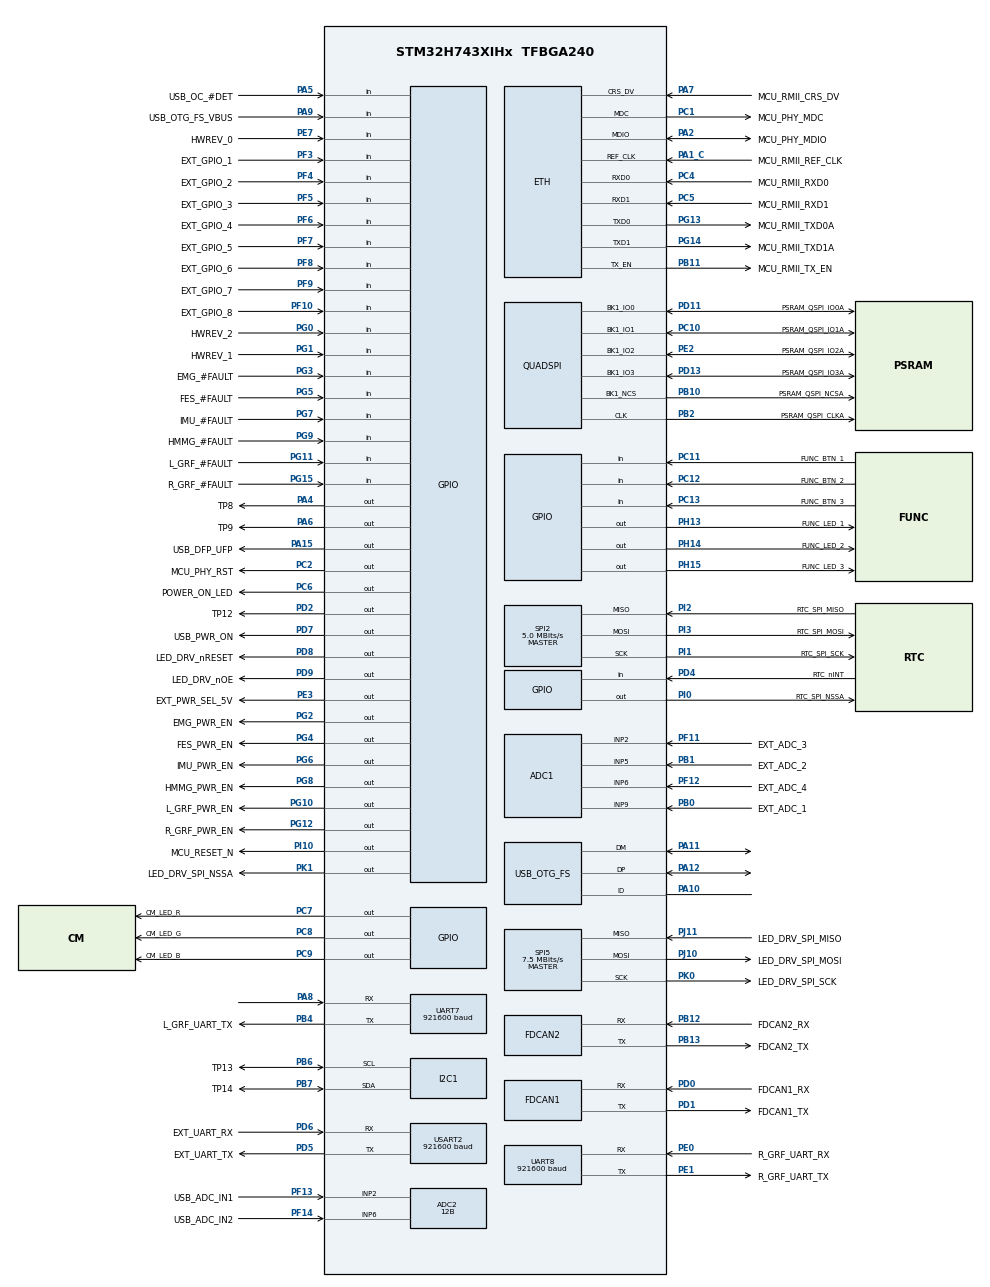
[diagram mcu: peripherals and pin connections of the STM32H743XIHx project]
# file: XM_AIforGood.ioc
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ADC1.Channel-6\#ChannelRegularConversion=ADC_CHANNEL_2
ADC1.Channel-7\#ChannelRegularConversion=ADC_CHANNEL_5
ADC1.Channel-8\#ChannelRegularConversion=ADC_CHANNEL_6
ADC1.Channel-9\#ChannelRegularConversion=ADC_CHANNEL_9
ADC1.ClockPrescaler=ADC_CLOCK_ASYNC_DIV4
ADC1.ConversionDataManagement=ADC_CONVERSIONDATA_DMA_CIRCULAR
ADC1.EOCSelection=ADC_EOC_SEQ_CONV
ADC1.ExternalTrigConv=ADC_EXTERNALTRIG_T2_TRGO
ADC1.NbrOfConversion=4
ADC1.NbrOfConversionFlag=1
ADC1.OffsetNumber-6\#ChannelRegularConversion=ADC_OFFSET_NONE
ADC1.OffsetNumber-7\#ChannelRegularConversion=ADC_OFFSET_NONE
ADC1.OffsetNumber-8\#ChannelRegularConversion=ADC_OFFSET_NONE
ADC1.OffsetNumber-9\#ChannelRegularConversion=ADC_OFFSET_NONE
ADC1.OffsetSignedSaturation-6\#ChannelRegularConversion=DISABLE
ADC1.OffsetSignedSaturation-7\#ChannelRegularConversion=DISABLE
ADC1.OffsetSignedSaturation-8\#ChannelRegularConversion=DISABLE
ADC1.OffsetSignedSaturation-9\#ChannelRegularConversion=DISABLE
ADC1.Overrun=ADC_OVR_DATA_OVERWRITTEN
ADC1.Rank-6\#ChannelRegularConversion=1
ADC1.Rank-7\#ChannelRegularConversion=2
ADC1.Rank-8\#ChannelRegularConversion=3
ADC1.Rank-9\#ChannelRegularConversion=4
ADC1.SamplingTime-6\#ChannelRegularConversion=ADC_SAMPLETIME_387CYCLES_5
ADC1.SamplingTime-7\#ChannelRegularConversion=ADC_SAMPLETIME_387CYCLES_5
ADC1.SamplingTime-8\#ChannelRegularConversion=ADC_SAMPLETIME_387CYCLES_5
ADC1.SamplingTime-9\#ChannelRegularConversion=ADC_SAMPLETIME_387CYCLES_5
ADC1.master=1
ADC2.Channel-2\#ChannelRegularConversion=ADC_CHANNEL_2
ADC2.Channel-3\#ChannelRegularConversion=ADC_CHANNEL_6
ADC2.ClockPrescaler=ADC_CLOCK_ASYNC_DIV4
ADC2.ConversionDataManagement=ADC_CONVERSIONDATA_DMA_CIRCULAR
ADC2.EOCSelection=ADC_EOC_SEQ_CONV
ADC2.ExternalTrigConv=ADC_EXTERNALTRIG_T2_TRGO
ADC2.NbrOfConversion=2
ADC2.NbrOfConversionFlag=1
ADC2.OffsetNumber-2\#ChannelRegularConversion=ADC_OFFSET_NONE
ADC2.OffsetNumber-3\#ChannelRegularConversion=ADC_OFFSET_NONE
ADC2.OffsetSignedSaturation-2\#ChannelRegularConversion=DISABLE
ADC2.Overrun=ADC_OVR_DATA_OVERWRITTEN
ADC2.Rank-2\#ChannelRegularConversion=1
ADC2.Rank-3\#ChannelRegularConversion=2
ADC2.Resolution=ADC_RESOLUTION_12B
ADC2.SamplingTime-2\#ChannelRegularConversion=ADC_SAMPLETIME_810CYCLES_5
ADC2.SamplingTime-3\#ChannelRegularConversion=ADC_SAMPLETIME_810CYCLES_5
CORTEX_M7.AccessPermission-Cortex_Memory_Protection_Unit_Region0_Settings=MPU_REGION_FULL_ACCESS
CORTEX_M7.AccessPermission-Cortex_Memory_Protection_Unit_Region1_Settings=MPU_REGION_FULL_ACCESS
CORTEX_M7.AccessPermission-Cortex_Memory_Protection_Unit_Region2_Settings=MPU_REGION_FULL_ACCESS
CORTEX_M7.AccessPermission-Cortex_Memory_Protection_Unit_Region3_Settings=MPU_REGION_FULL_ACCESS
CORTEX_M7.BaseAddress-Cortex_Memory_Protection_Unit_Region0_Settings=0x30000000
CORTEX_M7.BaseAddress-Cortex_Memory_Protection_Unit_Region1_Settings=0x30040000
CORTEX_M7.BaseAddress-Cortex_Memory_Protection_Unit_Region2_Settings=0x38000000
CORTEX_M7.BaseAddress-Cortex_Memory_Protection_Unit_Region3_Settings=0x90000000
CORTEX_M7.CPU_DCache=Enabled
CORTEX_M7.CPU_ICache=Enabled
CORTEX_M7.DisableExec-Cortex_Memory_Protection_Unit_Region0_Settings=MPU_INSTRUCTION_ACCESS_DISABLE
CORTEX_M7.DisableExec-Cortex_Memory_Protection_Unit_Region1_Settings=MPU_INSTRUCTION_ACCESS_DISABLE
CORTEX_M7.DisableExec-Cortex_Memory_Protection_Unit_Region2_Settings=MPU_INSTRUCTION_ACCESS_DISABLE
CORTEX_M7.Enable-Cortex_Memory_Protection_Unit_Region0_Settings=MPU_REGION_ENABLE
CORTEX_M7.Enable-Cortex_Memory_Protection_Unit_Region1_Settings=MPU_REGION_ENABLE
CORTEX_M7.Enable-Cortex_Memory_Protection_Unit_Region2_Settings=MPU_REGION_ENABLE
CORTEX_M7.Enable-Cortex_Memory_Protection_Unit_Region3_Settings=MPU_REGION_ENABLE
CORTEX_M7.IsBufferable-Cortex_Memory_Protection_Unit_Region0_Settings=MPU_ACCESS_NOT_BUFFERABLE
CORTEX_M7.IsCacheable-Cortex_Memory_Protection_Unit_Region0_Settings=MPU_ACCESS_NOT_CACHEABLE
CORTEX_M7.IsCacheable-Cortex_Memory_Protection_Unit_Region3_Settings=MPU_ACCESS_CACHEABLE
CORTEX_M7.IsShareable-Cortex_Memory_Protection_Unit_Region0_Settings=MPU_ACCESS_SHAREABLE
CORTEX_M7.IsShareable-Cortex_Memory_Protection_Unit_Region1_Settings=MPU_ACCESS_SHAREABLE
CORTEX_M7.IsShareable-Cortex_Memory_Protection_Unit_Region2_Settings=MPU_ACCESS_SHAREABLE
CORTEX_M7.MPU_Control=MPU_HFNMI_PRIVDEF
CORTEX_M7.Size-Cortex_Memory_Protection_Unit_Region0_Settings=MPU_REGION_SIZE_256KB
CORTEX_M7.Size-Cortex_Memory_Protection_Unit_Region1_Settings=MPU_REGION_SIZE_32KB
CORTEX_M7.Size-Cortex_Memory_Protection_Unit_Region2_Settings=MPU_REGION_SIZE_64KB
CORTEX_M7.Size-Cortex_Memory_Protection_Unit_Region3_Settings=MPU_REGION_SIZE_8MB
CORTEX_M7.TypeExtField-Cortex_Memory_Protection_Unit_Region0_Settings=MPU_TEX_LEVEL1
CORTEX_M7.TypeExtField-Cortex_Memory_Protection_Unit_Region1_Settings=MPU_TEX_LEVEL1
CORTEX_M7.TypeExtField-Cortex_Memory_Protection_Unit_Region2_Settings=MPU_TEX_LEVEL1
Dma.ADC1.1.Direction=DMA_PERIPH_TO_MEMORY
Dma.ADC1.1.EventEnable=DISABLE
Dma.ADC1.1.FIFOMode=DMA_FIFOMODE_DISABLE
Dma.ADC1.1.Instance=DMA1_Stream0
Dma.ADC1.1.MemDataAlignment=DMA_MDATAALIGN_HALFWORD
Dma.ADC1.1.MemInc=DMA_MINC_ENABLE
Dma.ADC1.1.Mode=DMA_CIRCULAR
Dma.ADC1.1.PeriphDataAlignment=DMA_PDATAALIGN_HALFWORD
Dma.ADC1.1.PeriphInc=DMA_PINC_DISABLE
Dma.ADC1.1.Polarity=HAL_DMAMUX_REQ_GEN_RISING
Dma.ADC1.1.Priority=DMA_PRIORITY_LOW
Dma.ADC1.1.RequestNumber=1
Dma.ADC1.1.SignalID=NONE
Dma.ADC1.1.SyncEnable=DISABLE
Dma.ADC1.1.SyncPolarity=HAL_DMAMUX_SYNC_NO_EVENT
Dma.ADC1.1.SyncRequestNumber=1
Dma.ADC1.1.SyncSignalID=NONE
Dma.ADC2.2.Direction=DMA_PERIPH_TO_MEMORY
Dma.ADC2.2.EventEnable=DISABLE
Dma.ADC2.2.FIFOMode=DMA_FIFOMODE_DISABLE
Dma.ADC2.2.Instance=DMA1_Stream1
Dma.ADC2.2.MemDataAlignment=DMA_MDATAALIGN_HALFWORD
Dma.ADC2.2.MemInc=DMA_MINC_ENABLE
Dma.ADC2.2.Mode=DMA_CIRCULAR
Dma.ADC2.2.PeriphDataAlignment=DMA_PDATAALIGN_HALFWORD
Dma.ADC2.2.PeriphInc=DMA_PINC_DISABLE
Dma.ADC2.2.Polarity=HAL_DMAMUX_REQ_GEN_RISING
Dma.ADC2.2.Priority=DMA_PRIORITY_LOW
Dma.ADC2.2.RequestNumber=1
Dma.ADC2.2.SignalID=NONE
Dma.ADC2.2.SyncEnable=DISABLE
Dma.ADC2.2.SyncPolarity=HAL_DMAMUX_SYNC_NO_EVENT
Dma.ADC2.2.SyncRequestNumber=1
Dma.ADC2.2.SyncSignalID=NONE
Dma.Request0=UART8_RX
Dma.Request1=ADC1
Dma.Request10=UART7_TX
Dma.Request11=UART8_TX
Dma.Request2=ADC2
Dma.Request3=UART7_RX
Dma.Request4=USART2_RX
Dma.Request5=SPI2_TX
Dma.Request6=SPI2_RX
Dma.Request7=SPI5_TX
Dma.Request8=SPI5_RX
Dma.Request9=USART2_TX
Dma.SPI2_RX.6.Direction=DMA_PERIPH_TO_MEMORY
Dma.SPI2_RX.6.EventEnable=DISABLE
Dma.SPI2_RX.6.FIFOMode=DMA_FIFOMODE_DISABLE
Dma.SPI2_RX.6.Instance=DMA1_Stream6
Dma.SPI2_RX.6.MemDataAlignment=DMA_MDATAALIGN_BYTE
Dma.SPI2_RX.6.MemInc=DMA_MINC_ENABLE
Dma.SPI2_RX.6.Mode=DMA_NORMAL
Dma.SPI2_RX.6.PeriphDataAlignment=DMA_PDATAALIGN_BYTE
Dma.SPI2_RX.6.PeriphInc=DMA_PINC_DISABLE
Dma.SPI2_RX.6.Polarity=HAL_DMAMUX_REQ_GEN_RISING
Dma.SPI2_RX.6.Priority=DMA_PRIORITY_LOW
Dma.SPI2_RX.6.RequestNumber=1
Dma.SPI2_RX.6.SignalID=NONE
Dma.SPI2_RX.6.SyncEnable=DISABLE
Dma.SPI2_RX.6.SyncPolarity=HAL_DMAMUX_SYNC_NO_EVENT
Dma.SPI2_RX.6.SyncRequestNumber=1
Dma.SPI2_RX.6.SyncSignalID=NONE
Dma.SPI2_TX.5.Direction=DMA_MEMORY_TO_PERIPH
Dma.SPI2_TX.5.EventEnable=DISABLE
Dma.SPI2_TX.5.FIFOMode=DMA_FIFOMODE_DISABLE
Dma.SPI2_TX.5.Instance=DMA1_Stream5
Dma.SPI2_TX.5.MemDataAlignment=DMA_MDATAALIGN_BYTE
Dma.SPI2_TX.5.MemInc=DMA_MINC_ENABLE
Dma.SPI2_TX.5.Mode=DMA_NORMAL
Dma.SPI2_TX.5.PeriphDataAlignment=DMA_PDATAALIGN_BYTE
Dma.SPI2_TX.5.PeriphInc=DMA_PINC_DISABLE
Dma.SPI2_TX.5.Polarity=HAL_DMAMUX_REQ_GEN_RISING
Dma.SPI2_TX.5.Priority=DMA_PRIORITY_LOW
Dma.SPI2_TX.5.RequestNumber=1
Dma.SPI2_TX.5.SignalID=NONE
Dma.SPI2_TX.5.SyncEnable=DISABLE
Dma.SPI2_TX.5.SyncPolarity=HAL_DMAMUX_SYNC_NO_EVENT
Dma.SPI2_TX.5.SyncRequestNumber=1
Dma.SPI2_TX.5.SyncSignalID=NONE
Dma.SPI5_RX.8.Direction=DMA_PERIPH_TO_MEMORY
Dma.SPI5_RX.8.EventEnable=DISABLE
Dma.SPI5_RX.8.FIFOMode=DMA_FIFOMODE_DISABLE
Dma.SPI5_RX.8.Instance=DMA2_Stream0
Dma.SPI5_RX.8.MemDataAlignment=DMA_MDATAALIGN_BYTE
Dma.SPI5_RX.8.MemInc=DMA_MINC_ENABLE
Dma.SPI5_RX.8.Mode=DMA_NORMAL
Dma.SPI5_RX.8.PeriphDataAlignment=DMA_PDATAALIGN_BYTE
Dma.SPI5_RX.8.PeriphInc=DMA_PINC_DISABLE
Dma.SPI5_RX.8.Polarity=HAL_DMAMUX_REQ_GEN_RISING
Dma.SPI5_RX.8.Priority=DMA_PRIORITY_LOW
Dma.SPI5_RX.8.RequestNumber=1
Dma.SPI5_RX.8.SignalID=NONE
Dma.SPI5_RX.8.SyncEnable=DISABLE
Dma.SPI5_RX.8.SyncPolarity=HAL_DMAMUX_SYNC_NO_EVENT
Dma.SPI5_RX.8.SyncRequestNumber=1
Dma.SPI5_RX.8.SyncSignalID=NONE
Dma.SPI5_TX.7.Direction=DMA_MEMORY_TO_PERIPH
Dma.SPI5_TX.7.EventEnable=DISABLE
Dma.SPI5_TX.7.FIFOMode=DMA_FIFOMODE_DISABLE
Dma.SPI5_TX.7.Instance=DMA1_Stream7
Dma.SPI5_TX.7.MemDataAlignment=DMA_MDATAALIGN_BYTE
Dma.SPI5_TX.7.MemInc=DMA_MINC_ENABLE
Dma.SPI5_TX.7.Mode=DMA_NORMAL
Dma.SPI5_TX.7.PeriphDataAlignment=DMA_PDATAALIGN_BYTE
Dma.SPI5_TX.7.PeriphInc=DMA_PINC_DISABLE
Dma.SPI5_TX.7.Polarity=HAL_DMAMUX_REQ_GEN_RISING
Dma.SPI5_TX.7.Priority=DMA_PRIORITY_LOW
Dma.SPI5_TX.7.RequestNumber=1
Dma.SPI5_TX.7.SignalID=NONE
Dma.SPI5_TX.7.SyncEnable=DISABLE
Dma.SPI5_TX.7.SyncPolarity=HAL_DMAMUX_SYNC_NO_EVENT
Dma.SPI5_TX.7.SyncRequestNumber=1
Dma.SPI5_TX.7.SyncSignalID=NONE
Dma.UART7_RX.3.Direction=DMA_PERIPH_TO_MEMORY
Dma.UART7_RX.3.EventEnable=DISABLE
Dma.UART7_RX.3.FIFOMode=DMA_FIFOMODE_ENABLE
Dma.UART7_RX.3.FIFOThreshold=DMA_FIFO_THRESHOLD_1QUARTERFULL
Dma.UART7_RX.3.Instance=DMA1_Stream2
Dma.UART7_RX.3.MemBurst=DMA_MBURST_SINGLE
Dma.UART7_RX.3.MemDataAlignment=DMA_MDATAALIGN_BYTE
Dma.UART7_RX.3.MemInc=DMA_MINC_ENABLE
Dma.UART7_RX.3.Mode=DMA_CIRCULAR
Dma.UART7_RX.3.PeriphBurst=DMA_PBURST_SINGLE
Dma.UART7_RX.3.PeriphDataAlignment=DMA_PDATAALIGN_BYTE
Dma.UART7_RX.3.PeriphInc=DMA_PINC_DISABLE
Dma.UART7_RX.3.Polarity=HAL_DMAMUX_REQ_GEN_RISING
Dma.UART7_RX.3.Priority=DMA_PRIORITY_VERY_HIGH
Dma.UART7_RX.3.RequestNumber=1
Dma.UART7_RX.3.SignalID=NONE
Dma.UART7_RX.3.SyncEnable=DISABLE
Dma.UART7_RX.3.SyncPolarity=HAL_DMAMUX_SYNC_NO_EVENT
Dma.UART7_RX.3.SyncRequestNumber=1
Dma.UART7_RX.3.SyncSignalID=NONE
Dma.UART7_TX.10.Direction=DMA_MEMORY_TO_PERIPH
Dma.UART7_TX.10.EventEnable=DISABLE
Dma.UART7_TX.10.FIFOMode=DMA_FIFOMODE_DISABLE
Dma.UART7_TX.10.Instance=DMA2_Stream2
Dma.UART7_TX.10.MemDataAlignment=DMA_MDATAALIGN_BYTE
Dma.UART7_TX.10.MemInc=DMA_MINC_ENABLE
Dma.UART7_TX.10.Mode=DMA_NORMAL
Dma.UART7_TX.10.PeriphDataAlignment=DMA_PDATAALIGN_BYTE
Dma.UART7_TX.10.PeriphInc=DMA_PINC_DISABLE
Dma.UART7_TX.10.Polarity=HAL_DMAMUX_REQ_GEN_RISING
Dma.UART7_TX.10.Priority=DMA_PRIORITY_LOW
Dma.UART7_TX.10.RequestNumber=1
Dma.UART7_TX.10.SignalID=NONE
Dma.UART7_TX.10.SyncEnable=DISABLE
Dma.UART7_TX.10.SyncPolarity=HAL_DMAMUX_SYNC_NO_EVENT
Dma.UART7_TX.10.SyncRequestNumber=1
Dma.UART7_TX.10.SyncSignalID=NONE
Dma.UART8_RX.0.Direction=DMA_PERIPH_TO_MEMORY
Dma.UART8_RX.0.EventEnable=DISABLE
Dma.UART8_RX.0.FIFOMode=DMA_FIFOMODE_ENABLE
Dma.UART8_RX.0.FIFOThreshold=DMA_FIFO_THRESHOLD_1QUARTERFULL
Dma.UART8_RX.0.Instance=DMA1_Stream3
Dma.UART8_RX.0.MemBurst=DMA_MBURST_SINGLE
Dma.UART8_RX.0.MemDataAlignment=DMA_MDATAALIGN_BYTE
Dma.UART8_RX.0.MemInc=DMA_MINC_ENABLE
Dma.UART8_RX.0.Mode=DMA_CIRCULAR
Dma.UART8_RX.0.PeriphBurst=DMA_PBURST_SINGLE
Dma.UART8_RX.0.PeriphDataAlignment=DMA_PDATAALIGN_BYTE
Dma.UART8_RX.0.PeriphInc=DMA_PINC_DISABLE
Dma.UART8_RX.0.Polarity=HAL_DMAMUX_REQ_GEN_RISING
Dma.UART8_RX.0.Priority=DMA_PRIORITY_VERY_HIGH
Dma.UART8_RX.0.RequestNumber=1
Dma.UART8_RX.0.SignalID=NONE
Dma.UART8_RX.0.SyncEnable=DISABLE
Dma.UART8_RX.0.SyncPolarity=HAL_DMAMUX_SYNC_NO_EVENT
Dma.UART8_RX.0.SyncRequestNumber=1
Dma.UART8_RX.0.SyncSignalID=NONE
Dma.UART8_TX.11.Direction=DMA_MEMORY_TO_PERIPH
Dma.UART8_TX.11.EventEnable=DISABLE
Dma.UART8_TX.11.FIFOMode=DMA_FIFOMODE_DISABLE
Dma.UART8_TX.11.Instance=DMA2_Stream3
Dma.UART8_TX.11.MemDataAlignment=DMA_MDATAALIGN_BYTE
Dma.UART8_TX.11.MemInc=DMA_MINC_ENABLE
Dma.UART8_TX.11.Mode=DMA_NORMAL
Dma.UART8_TX.11.PeriphDataAlignment=DMA_PDATAALIGN_BYTE
Dma.UART8_TX.11.PeriphInc=DMA_PINC_DISABLE
Dma.UART8_TX.11.Polarity=HAL_DMAMUX_REQ_GEN_RISING
Dma.UART8_TX.11.Priority=DMA_PRIORITY_LOW
Dma.UART8_TX.11.RequestNumber=1
Dma.UART8_TX.11.SignalID=NONE
Dma.UART8_TX.11.SyncEnable=DISABLE
Dma.UART8_TX.11.SyncPolarity=HAL_DMAMUX_SYNC_NO_EVENT
Dma.UART8_TX.11.SyncRequestNumber=1
Dma.UART8_TX.11.SyncSignalID=NONE
Dma.USART2_RX.4.Direction=DMA_PERIPH_TO_MEMORY
Dma.USART2_RX.4.EventEnable=DISABLE
Dma.USART2_RX.4.FIFOMode=DMA_FIFOMODE_ENABLE
Dma.USART2_RX.4.FIFOThreshold=DMA_FIFO_THRESHOLD_1QUARTERFULL
Dma.USART2_RX.4.Instance=DMA1_Stream4
Dma.USART2_RX.4.MemBurst=DMA_MBURST_SINGLE
Dma.USART2_RX.4.MemDataAlignment=DMA_MDATAALIGN_BYTE
Dma.USART2_RX.4.MemInc=DMA_MINC_ENABLE
Dma.USART2_RX.4.Mode=DMA_CIRCULAR
Dma.USART2_RX.4.PeriphBurst=DMA_PBURST_SINGLE
Dma.USART2_RX.4.PeriphDataAlignment=DMA_PDATAALIGN_BYTE
Dma.USART2_RX.4.PeriphInc=DMA_PINC_DISABLE
Dma.USART2_RX.4.Polarity=HAL_DMAMUX_REQ_GEN_RISING
Dma.USART2_RX.4.Priority=DMA_PRIORITY_VERY_HIGH
Dma.USART2_RX.4.RequestNumber=1
Dma.USART2_RX.4.SignalID=NONE
Dma.USART2_RX.4.SyncEnable=DISABLE
Dma.USART2_RX.4.SyncPolarity=HAL_DMAMUX_SYNC_NO_EVENT
Dma.USART2_RX.4.SyncRequestNumber=1
Dma.USART2_RX.4.SyncSignalID=NONE
Dma.USART2_TX.9.Direction=DMA_MEMORY_TO_PERIPH
Dma.USART2_TX.9.EventEnable=DISABLE
Dma.USART2_TX.9.FIFOMode=DMA_FIFOMODE_DISABLE
Dma.USART2_TX.9.Instance=DMA2_Stream1
Dma.USART2_TX.9.MemDataAlignment=DMA_MDATAALIGN_BYTE
Dma.USART2_TX.9.MemInc=DMA_MINC_ENABLE
Dma.USART2_TX.9.Mode=DMA_NORMAL
Dma.USART2_TX.9.PeriphDataAlignment=DMA_PDATAALIGN_BYTE
Dma.USART2_TX.9.PeriphInc=DMA_PINC_DISABLE
Dma.USART2_TX.9.Polarity=HAL_DMAMUX_REQ_GEN_RISING
Dma.USART2_TX.9.Priority=DMA_PRIORITY_LOW
Dma.USART2_TX.9.RequestNumber=1
Dma.USART2_TX.9.SignalID=NONE
Dma.USART2_TX.9.SyncEnable=DISABLE
Dma.USART2_TX.9.SyncPolarity=HAL_DMAMUX_SYNC_NO_EVENT
Dma.USART2_TX.9.SyncRequestNumber=1
Dma.USART2_TX.9.SyncSignalID=NONE
ETH.ETH_RX_DESC_CNT=8
ETH.ETH_TX_DESC_CNT=8
ETH.MediaInterface=HAL_ETH_RMII_MODE
FATFS._FS_RPATH=0
FATFS._MAX_SS=4096
FATFS._USE_LFN=2
FDCAN1.AutoRetransmission=ENABLE
FDCAN1.CalculateBaudRateNominal=1000000
FDCAN1.CalculateTimeBitNominal=1000
FDCAN1.CalculateTimeQuantumNominal=125.0
FDCAN1.DataSyncJumpWidth=4
FDCAN1.DataTimeSeg1=11
FDCAN1.DataTimeSeg2=4
FDCAN1.FrameFormat=FDCAN_FRAME_FD_BRS
FDCAN1.NominalPrescaler=10
FDCAN1.NominalSyncJumpWidth=2
FDCAN1.NominalTimeSeg1=5
FDCAN1.NominalTimeSeg2=2
FDCAN1.RxBufferSize=FDCAN_DATA_BYTES_64
FDCAN1.RxBuffersNbr=0
FDCAN1.RxFifo0ElmtSize=FDCAN_DATA_BYTES_64
FDCAN1.RxFifo0ElmtsNbr=37
FDCAN1.RxFifo1ElmtSize=FDCAN_DATA_BYTES_64
FDCAN1.RxFifo1ElmtsNbr=0
FDCAN1.StdFiltersNbr=28
FDCAN1.TransmitPause=ENABLE
FDCAN1.TxBuffersNbr=0
FDCAN1.TxElmtSize=FDCAN_DATA_BYTES_64
FDCAN1.TxEventsNbr=0
FDCAN1.TxFifoQueueElmtsNbr=32
FDCAN1.TxFifoQueueMode=FDCAN_TX_QUEUE_OPERATION
FDCAN2.AutoRetransmission=ENABLE
FDCAN2.CalculateBaudRateNominal=1000000
FDCAN2.CalculateTimeBitNominal=1000
FDCAN2.CalculateTimeQuantumNominal=125.0
FDCAN2.DataSyncJumpWidth=4
FDCAN2.DataTimeSeg1=11
FDCAN2.DataTimeSeg2=4
FDCAN2.FrameFormat=FDCAN_FRAME_FD_BRS
FDCAN2.MessageRAMOffset=1280
FDCAN2.NominalPrescaler=10
FDCAN2.NominalSyncJumpWidth=2
FDCAN2.NominalTimeSeg1=5
FDCAN2.NominalTimeSeg2=2
FDCAN2.RxBufferSize=FDCAN_DATA_BYTES_64
FDCAN2.RxFifo0ElmtSize=FDCAN_DATA_BYTES_64
FDCAN2.RxFifo0ElmtsNbr=37
FDCAN2.RxFifo1ElmtSize=FDCAN_DATA_BYTES_64
FDCAN2.StdFiltersNbr=28
FDCAN2.TransmitPause=ENABLE
FDCAN2.TxElmtSize=FDCAN_DATA_BYTES_64
FDCAN2.TxFifoQueueElmtsNbr=32
FDCAN2.TxFifoQueueMode=FDCAN_TX_QUEUE_OPERATION
FREERTOS.HEAP_NUMBER=4
FREERTOS.Tasks01=DefaultTask,8,2048,StartDefaultTask,Default,NULL,Static,DefaultTaskBuffer,DefaultTaskControlBlock;UserTask,54,8192,StartUserTask,As weak,NULL,Dynamic,NULL,NULL;StartupTask,55,512,StartStartupTask,As weak,NULL,Dynamic,NULL,NULL
FREERTOS.configCHECK_FOR_STACK_OVERFLOW=2
FREERTOS.configENABLE_FPU=1
FREERTOS.configTOTAL_HEAP_SIZE=102400
FREERTOS.configUSE_NEWLIB_REENTRANT=1
I2C1.Timing=0x307075B1
LWIP.DEFAULT_RAW_RECVMBOX_SIZE=6
LWIP.DEFAULT_TCP_RECVMBOX_SIZE=6
LWIP.DEFAULT_THREAD_PRIO=24
LWIP.DEFAULT_THREAD_STACKSIZE=512
LWIP.DEFAULT_UDP_RECVMBOX_SIZE=24
LWIP.DHCP_DEBUG=LWIP_DBG_OFF
LWIP.ETHARP_DEBUG=LWIP_DBG_OFF
LWIP.GATEWAY_ADDRESS=192.168.010.001
LWIP.IP_ADDRESS=192.168.010.010
LWIP.IP_DEBUG=LWIP_DBG_OFF
LWIP.IP_FRAG=0
LWIP.IP_REASSEMBLY=0
LWIP.LWIP_COMPAT_SOCKETS=0
LWIP.LWIP_DBG_MIN_LEVEL=LWIP_DBG_LEVEL_ALL
LWIP.LWIP_DBG_TYPES_ON=LWIP_DBG_OFF
LWIP.LWIP_DHCP=0
LWIP.LWIP_NETIF_API=1
LWIP.LWIP_NETIF_HOSTNAME=1
LWIP.LWIP_NETIF_HOSTNAME_NAME=XM10-Rev2.0
LWIP.LWIP_NETIF_STATUS_CALLBACK=1
LWIP.LWIP_NETIF_TX_SINGLE_PBUF=1
LWIP.LWIP_POSIX_SOCKETS_IO_NAMES=0
LWIP.LWIP_RAM_HEAP_POINTER=0x30030000
LWIP.LWIP_SINGLE_NETIF=1
LWIP.LWIP_SOCKET=0
LWIP.LWIP_SO_RCVTIMEO=0
LWIP.LWIP_SO_SNDTIMEO=0
LWIP.LWIP_TCP=0
LWIP.LWIP_TCPIP_CORE_LOCKING=1
LWIP.MEMP_NUM_NETBUF=16
LWIP.MEMP_NUM_NETCONN=8
LWIP.MEMP_NUM_PBUF=32
LWIP.MEMP_NUM_REASSDATA=1
LWIP.MEMP_NUM_SYS_TIMEOUT=6
LWIP.MEMP_NUM_TCPIP_MSG_API=12
LWIP.MEMP_NUM_TCPIP_MSG_INPKT=16
LWIP.MEMP_NUM_TCP_PCB_LISTEN=10
LWIP.MEMP_NUM_TCP_SEG=24
LWIP.MEMP_NUM_UDP_PCB=6
LWIP.MEM_DEBUG=LWIP_DBG_OFF
LWIP.MEM_SIZE=32768
LWIP.NETIF_DEBUG=LWIP_DBG_OFF
LWIP.NETMASK_ADDRESS=255.255.255.000
LWIP.PBUF_DEBUG=LWIP_DBG_OFF
LWIP.PBUF_POOL_BUFSIZE=1524
LWIP.PBUF_POOL_SIZE=32
LWIP.TCPIP_DEBUG=LWIP_DBG_OFF
LWIP.TCPIP_MBOX_SIZE=16
LWIP.TCPIP_THREAD_NAME="TCP/IP"
LWIP.TCPIP_THREAD_PRIO=32
LWIP.TCP_MSS=1460
LWIP.TCP_QUEUE_OOSEQ=1
LWIP.TCP_SND_BUF=8760
LWIP.TCP_WND=14600
LWIP.UDP_DEBUG=LWIP_DBG_OFF
LWIP.Version=v2.2.1_Cube
Mcu.Family=STM32H7
Mcu.Name=STM32H743XIHx
Mcu.Package=TFBGA240
Mdma.MDMA_Channel0.QUADSPI_FIFO_TH.0.BlockCount=0
Mdma.MDMA_Channel0.QUADSPI_FIFO_TH.0.BlockDataLength=0
Mdma.MDMA_Channel0.QUADSPI_FIFO_TH.0.BufferTransferLength=4
Mdma.MDMA_Channel0.QUADSPI_FIFO_TH.0.CircularMode=MDMA_LINEAR_LIST
Mdma.MDMA_Channel0.QUADSPI_FIFO_TH.0.DataAlignment=MDMA_DATAALIGN_PACKENABLE
Mdma.MDMA_Channel0.QUADSPI_FIFO_TH.0.DestBlockAddressOffset=0
Mdma.MDMA_Channel0.QUADSPI_FIFO_TH.0.DestBurst=MDMA_DEST_BURST_SINGLE
Mdma.MDMA_Channel0.QUADSPI_FIFO_TH.0.DestDataSize=MDMA_DEST_DATASIZE_BYTE
Mdma.MDMA_Channel0.QUADSPI_FIFO_TH.0.DestinationInc=MDMA_DEST_INC_BYTE
Mdma.MDMA_Channel0.QUADSPI_FIFO_TH.0.DstAddress=0
Mdma.MDMA_Channel0.QUADSPI_FIFO_TH.0.Endianness=MDMA_LITTLE_ENDIANNESS_PRESERVE
Mdma.MDMA_Channel0.QUADSPI_FIFO_TH.0.Instance=MDMA_Channel0
Mdma.MDMA_Channel0.QUADSPI_FIFO_TH.0.MaskAddress=0
Mdma.MDMA_Channel0.QUADSPI_FIFO_TH.0.MaskData=0
Mdma.MDMA_Channel0.QUADSPI_FIFO_TH.0.Priority=MDMA_PRIORITY_HIGH
Mdma.MDMA_Channel0.QUADSPI_FIFO_TH.0.Rank=First
Mdma.MDMA_Channel0.QUADSPI_FIFO_TH.0.SourceBlockAddressOffset=0
Mdma.MDMA_Channel0.QUADSPI_FIFO_TH.0.SourceBurst=MDMA_SOURCE_BURST_SINGLE
Mdma.MDMA_Channel0.QUADSPI_FIFO_TH.0.SourceDataSize=MDMA_SRC_DATASIZE_BYTE
Mdma.MDMA_Channel0.QUADSPI_FIFO_TH.0.SourceInc=MDMA_SRC_INC_BYTE
Mdma.MDMA_Channel0.QUADSPI_FIFO_TH.0.SrcAddress=0
Mdma.MDMA_Channel0.QUADSPI_FIFO_TH.0.TransferTriggerMode=MDMA_BUFFER_TRANSFER
Mdma.MDMA_Channel0.Request0=QUADSPI_FIFO_TH
Mdma.MDMA_Channel0.RequestsNb=1
Mdma.RequestSet0=MDMA_Channel0
Mdma.RequestSetsNb=1
NVIC.DMA1_Stream0_IRQn=true\:7\:0\:true\:false\:true\:true\:false\:true\:true
NVIC.DMA1_Stream1_IRQn=true\:7\:0\:true\:false\:true\:true\:false\:true\:true
NVIC.DMA1_Stream2_IRQn=true\:6\:0\:true\:false\:true\:true\:false\:true\:true
NVIC.DMA1_Stream3_IRQn=true\:6\:0\:true\:false\:true\:false\:false\:true\:true
NVIC.DMA1_Stream4_IRQn=true\:6\:0\:true\:false\:true\:true\:false\:true\:true
NVIC.DMA1_Stream5_IRQn=true\:6\:0\:true\:false\:true\:true\:false\:true\:true
NVIC.DMA1_Stream6_IRQn=true\:6\:0\:true\:false\:true\:true\:false\:true\:true
NVIC.DMA1_Stream7_IRQn=true\:6\:0\:true\:false\:true\:true\:false\:true\:true
NVIC.DMA2_Stream0_IRQn=true\:6\:0\:true\:false\:true\:true\:false\:true\:true
NVIC.DMA2_Stream1_IRQn=true\:6\:0\:true\:false\:true\:true\:false\:true\:true
NVIC.DMA2_Stream2_IRQn=true\:6\:0\:true\:false\:true\:true\:false\:true\:true
NVIC.DMA2_Stream3_IRQn=true\:6\:0\:true\:false\:true\:true\:false\:true\:true
NVIC.ETH_IRQn=true\:5\:0\:true\:false\:true\:true\:true\:true\:true
NVIC.FDCAN1_IT0_IRQn=true\:5\:0\:true\:false\:true\:false\:true\:true\:true
NVIC.FDCAN1_IT1_IRQn=true\:5\:0\:true\:false\:true\:false\:true\:true\:true
NVIC.FDCAN2_IT0_IRQn=true\:5\:0\:true\:false\:true\:false\:true\:true\:true
NVIC.FDCAN2_IT1_IRQn=true\:5\:0\:true\:false\:true\:false\:true\:true\:true
NVIC.MDMA_IRQn=true\:6\:0\:true\:false\:true\:true\:false\:true\:true
NVIC.PriorityGroup=NVIC_PRIORITYGROUP_4
NVIC.QUADSPI_IRQn=true\:6\:0\:true\:false\:true\:true\:true\:true\:true
NVIC.SPI2_IRQn=true\:6\:0\:true\:false\:true\:true\:false\:true\:true
NVIC.SPI5_IRQn=true\:6\:0\:true\:false\:true\:true\:false\:true\:true
NVIC.TIM1_UP_IRQn=true\:15\:0\:false\:false\:true\:false\:false\:true\:true
NVIC.TIM7_IRQn=true\:6\:0\:true\:false\:true\:true\:true\:true\:true
NVIC.TimeBase=TIM1_UP_IRQn
NVIC.TimeBaseIP=TIM1
NVIC.UART7_IRQn=true\:6\:0\:true\:false\:true\:true\:true\:true\:true
NVIC.UART8_IRQn=true\:6\:0\:true\:false\:true\:true\:true\:true\:true
NVIC.USART2_IRQn=true\:6\:0\:true\:false\:true\:true\:true\:true\:true
PA10.Mode=OTG/Dual_Role_Device
PA10.Signal=USB_OTG_FS_ID
PA11.GPIO_Speed=GPIO_SPEED_FREQ_VERY_HIGH
PA11.Mode=OTG/Dual_Role_Device
PA11.Signal=USB_OTG_FS_DM
PA12.GPIO_Speed=GPIO_SPEED_FREQ_VERY_HIGH
PA12.Mode=OTG/Dual_Role_Device
PA12.Signal=USB_OTG_FS_DP
PA13\ (JTMS/SWDIO).GPIO_Label=DEBUG_SWDIO
PA13\ (JTMS/SWDIO).Mode=Trace_Asynchronous_SW
PA13\ (JTMS/SWDIO).Signal=DEBUG_JTMS-SWDIO
PA14\ (JTCK/SWCLK).GPIO_Label=DEBUG_SWCLK
PA14\ (JTCK/SWCLK).Mode=Trace_Asynchronous_SW
PA14\ (JTCK/SWCLK).Signal=DEBUG_JTCK-SWCLK
PA15\ (JTDI).GPIO_Label=USB_DFP_UFP
PA15\ (JTDI).GPIO_Speed=GPIO_SPEED_FREQ_LOW
PA15\ (JTDI).Signal=GPIO_Output
PA1_C.GPIO_Label=MCU_RMII_REF_CLK
PA1_C.Mode=RMII
PA1_C.Signal=ETH_REF_CLK
PA2.GPIO_Label=MCU_PHY_MDIO
PA2.Mode=RMII
PA2.Signal=ETH_MDIO
PA4.GPIO_Label=TP8
PA4.Signal=GPIO_Output
PA5.GPIO_Label=USB_OC_\#DET
PA5.GPIO_PuPd=GPIO_NOPULL
PA5.Signal=GPIO_Input
PA6.GPIO_Label=TP9
PA6.GPIO_PuPd=GPIO_PULLDOWN
PA6.Signal=GPIO_Output
PA7.GPIO_Label=MCU_RMII_CRS_DV
PA7.Mode=RMII
PA7.Signal=ETH_CRS_DV
PA8.Mode=Asynchronous
PA8.Signal=UART7_RX
PA9.GPIO_Label=USB_OTG_FS_VBUS
PA9.GPIO_PuPd=GPIO_NOPULL
PA9.Signal=GPIO_Input
PB0.GPIO_Label=EXT_ADC_1
PB0.Signal=ADCx_INP9
PB1.GPIO_Label=EXT_ADC_2
PB1.Signal=ADCx_INP5
PB10.GPIO_Label=PSRAM_QSPI_NCSA
PB10.GPIO_Speed=GPIO_SPEED_FREQ_VERY_HIGH
PB10.Mode=Single Bank 1
PB10.Signal=QUADSPI_BK1_NCS
PB11.GPIO_Label=MCU_RMII_TX_EN
PB11.Mode=RMII
PB11.Signal=ETH_TX_EN
PB12.GPIO_Label=FDCAN2_RX
PB12.Mode=FDCAN_Activate
PB12.Signal=FDCAN2_RX
PB13.GPIO_Label=FDCAN2_TX
PB13.Mode=FDCAN_Activate
PB13.Signal=FDCAN2_TX
PB2.GPIO_Label=PSRAM_QSPI_CLKA
PB2.GPIO_Speed=GPIO_SPEED_FREQ_VERY_HIGH
PB2.Mode=Single Bank 1
PB2.Signal=QUADSPI_CLK
PB3\ (JTDO/TRACESWO).GPIO_Label=DEBUG_TRACE_SWO
PB3\ (JTDO/TRACESWO).Mode=Trace_Asynchronous_SW
PB3\ (JTDO/TRACESWO).Signal=DEBUG_JTDO-SWO
PB4\ (NJTRST).GPIO_Label=L_GRF_UART_TX
PB4\ (NJTRST).Mode=Asynchronous
PB4\ (NJTRST).Signal=UART7_TX
PB6.GPIO_Label=TP13
PB6.Mode=I2C
PB6.Signal=I2C1_SCL
PB7.GPIO_Label=TP14
PB7.Mode=I2C
PB7.Signal=I2C1_SDA
PC1.GPIO_Label=MCU_PHY_MDC
PC1.Mode=RMII
PC1.Signal=ETH_MDC
PC10.GPIO_Label=PSRAM_QSPI_IO1A
PC10.GPIO_Speed=GPIO_SPEED_FREQ_VERY_HIGH
PC10.Mode=Single Bank 1
PC10.Signal=QUADSPI_BK1_IO1
PC11.GPIO_Label=FUNC_BTN_1
PC11.Signal=GPIO_Input
PC12.GPIO_Label=FUNC_BTN_2
PC12.Signal=GPIO_Input
PC13.GPIO_Label=FUNC_BTN_3
PC13.Signal=GPIO_Input
PC15-OSC32_OUT\ (OSC32_OUT).Signal=RCC_OSC32_OUT
PC2.GPIO_Label=MCU_PHY_RST
PC2.Signal=GPIO_Output
PC4.GPIO_Label=MCU_RMII_RXD0
PC4.Mode=RMII
PC4.Signal=ETH_RXD0
PC5.GPIO_Label=MCU_RMII_RXD1
PC5.Mode=RMII
PC5.Signal=ETH_RXD1
PC6.GPIO_Label=POWER_ON_LED
PC6.Signal=GPIO_Output
PC7.GPIO_Label=CM_LED_R
PC7.Signal=GPIO_Output
PC8.GPIO_Label=CM_LED_G
PC8.Signal=GPIO_Output
PC9.GPIO_Label=CM_LED_B
PC9.Signal=GPIO_Output
PD0.GPIO_Label=FDCAN1_RX
PD0.Mode=FDCAN_Activate
PD0.Signal=FDCAN1_RX
PD1.GPIO_Label=FDCAN1_TX
PD1.Mode=FDCAN_Activate
PD1.Signal=FDCAN1_TX
PD11.GPIO_Label=PSRAM_QSPI_IO0A
PD11.GPIO_Speed=GPIO_SPEED_FREQ_VERY_HIGH
PD11.Mode=Single Bank 1
PD11.Signal=QUADSPI_BK1_IO0
PD13.GPIO_Label=PSRAM_QSPI_IO3A
PD13.GPIO_Speed=GPIO_SPEED_FREQ_VERY_HIGH
PD13.Mode=Single Bank 1
PD13.Signal=QUADSPI_BK1_IO3
PD2.GPIO_Label=TP12
PD2.GPIO_PuPd=GPIO_PULLDOWN
PD2.Signal=GPIO_Output
PD4.GPIO_Label=RTC_nINT
PD4.Signal=GPIO_Input
PD5.GPIO_Label=EXT_UART_TX
PD5.Mode=Asynchronous
PD5.Signal=USART2_TX
PD6.GPIO_Label=EXT_UART_RX
PD6.Mode=Asynchronous
PD6.Signal=USART2_RX
PD7.GPIO_Label=USB_PWR_ON
PD7.GPIO_PuPd=GPIO_NOPULL
PD7.GPIO_Speed=GPIO_SPEED_FREQ_LOW
PD7.Signal=GPIO_Output
PD8.GPIO_Label=LED_DRV_nRESET
PD8.Signal=GPIO_Output
PD9.GPIO_Label=LED_DRV_nOE
PD9.Signal=GPIO_Output
PE0.GPIO_Label=R_GRF_UART_RX
PE0.Mode=Asynchronous
PE0.Signal=UART8_RX
PE1.GPIO_Label=R_GRF_UART_TX
PE1.Mode=Asynchronous
PE1.Signal=UART8_TX
PE2.GPIO_Label=PSRAM_QSPI_IO2A
PE2.GPIO_Speed=GPIO_SPEED_FREQ_VERY_HIGH
PE2.Mode=Single Bank 1
PE2.Signal=QUADSPI_BK1_IO2
PE3.GPIO_Label=EXT_PWR_SEL_5V
PE3.Signal=GPIO_Output
PE7.GPIO_Label=HWREV_0
PE7.Signal=GPIO_Input
PF10.GPIO_Label=EXT_GPIO_8
PF10.GPIO_PuPd=GPIO_NOPULL
PF10.Signal=GPIO_Input
PF11.GPIO_Label=EXT_ADC_3
PF11.Mode=IN2-Single-Ended
PF11.Signal=ADC1_INP2
PF12.GPIO_Label=EXT_ADC_4
PF12.Mode=IN6-Single-Ended
PF12.Signal=ADC1_INP6
PF13.GPIO_Label=USB_ADC_IN1
PF13.Mode=IN2-Single-Ended
PF13.Signal=ADC2_INP2
PF14.GPIO_Label=USB_ADC_IN2
PF14.Mode=IN6-Single-Ended
PF14.Signal=ADC2_INP6
PF3.GPIO_Label=EXT_GPIO_1
PF3.GPIO_PuPd=GPIO_NOPULL
PF3.Signal=GPIO_Input
PF4.GPIO_Label=EXT_GPIO_2
PF4.GPIO_PuPd=GPIO_NOPULL
PF4.Signal=GPIO_Input
PF5.GPIO_Label=EXT_GPIO_3
PF5.GPIO_PuPd=GPIO_NOPULL
PF5.Signal=GPIO_Input
PF6.GPIO_Label=EXT_GPIO_4
PF6.GPIO_PuPd=GPIO_NOPULL
PF6.Signal=GPIO_Input
PF7.GPIO_Label=EXT_GPIO_5
PF7.GPIO_PuPd=GPIO_NOPULL
PF7.Signal=GPIO_Input
PF8.GPIO_Label=EXT_GPIO_6
PF8.GPIO_PuPd=GPIO_NOPULL
PF8.Signal=GPIO_Input
PF9.GPIO_Label=EXT_GPIO_7
PF9.GPIO_PuPd=GPIO_NOPULL
PF9.Signal=GPIO_Input
PG0.GPIO_Label=HWREV_2
PG0.Signal=GPIO_Input
PG1.GPIO_Label=HWREV_1
PG1.Signal=GPIO_Input
PG10.GPIO_Label=L_GRF_PWR_EN
PG10.Signal=GPIO_Output
PG11.GPIO_Label=L_GRF_\#FAULT
PG11.Signal=GPIO_Input
PG12.GPIO_Label=R_GRF_PWR_EN
PG12.Signal=GPIO_Output
PG13.GPIO_Label=MCU_RMII_TXD0A
PG13.Mode=RMII
PG13.Signal=ETH_TXD0
PG14.GPIO_Label=MCU_RMII_TXD1A
PG14.Mode=RMII
PG14.Signal=ETH_TXD1
PG15.GPIO_Label=R_GRF_\#FAULT
PG15.Signal=GPIO_Input
PG2.GPIO_Label=EMG_PWR_EN
PG2.Signal=GPIO_Output
PG3.GPIO_Label=EMG_\#FAULT
PG3.Signal=GPIO_Input
PG4.GPIO_Label=FES_PWR_EN
PG4.Signal=GPIO_Output
PG5.GPIO_Label=FES_\#FAULT
PG5.Signal=GPIO_Input
PG6.GPIO_Label=IMU_PWR_EN
PG6.Signal=GPIO_Output
PG7.GPIO_Label=IMU_\#FAULT
PG7.Signal=GPIO_Input
PG8.GPIO_Label=HMMG_PWR_EN
PG8.Signal=GPIO_Output
PG9.GPIO_Label=HMMG_\#FAULT
PG9.Signal=GPIO_Input
PH0-OSC_IN\ (PH0).Mode=HSE-External-Oscillator
PH0-OSC_IN\ (PH0).Signal=RCC_OSC_IN
PH1-OSC_OUT\ (PH1).Mode=HSE-External-Oscillator
PH1-OSC_OUT\ (PH1).Signal=RCC_OSC_OUT
PH13.GPIO_Label=FUNC_LED_1
PH13.Signal=GPIO_Output
PH14.GPIO_Label=FUNC_LED_2
PH14.Signal=GPIO_Output
PH15.GPIO_Label=FUNC_LED_3
PH15.Signal=GPIO_Output
PI0.GPIO_Label=RTC_SPI_NSSA
PI0.GPIO_Speed=GPIO_SPEED_FREQ_MEDIUM
PI0.PinState=GPIO_PIN_SET
PI0.Signal=GPIO_Output
PI1.GPIO_Label=RTC_SPI_SCK
PI1.GPIO_Speed=GPIO_SPEED_FREQ_MEDIUM
PI1.Mode=Full_Duplex_Master
PI1.Signal=SPI2_SCK
PI10.GPIO_Label=MCU_RESET_N
PI10.Signal=GPIO_Output
PI2.GPIO_Label=RTC_SPI_MISO
PI2.GPIO_Speed=GPIO_SPEED_FREQ_MEDIUM
PI2.Mode=Full_Duplex_Master
PI2.Signal=SPI2_MISO
PI3.GPIO_Label=RTC_SPI_MOSI
PI3.GPIO_Speed=GPIO_SPEED_FREQ_MEDIUM
PI3.Mode=Full_Duplex_Master
PI3.Signal=SPI2_MOSI
PJ10.GPIO_Label=LED_DRV_SPI_MOSI
PJ10.GPIO_Speed=GPIO_SPEED_FREQ_MEDIUM
PJ10.Mode=Full_Duplex_Master
PJ10.Signal=SPI5_MOSI
PJ11.GPIO_Label=LED_DRV_SPI_MISO
PJ11.GPIO_Speed=GPIO_SPEED_FREQ_MEDIUM
PJ11.Mode=Full_Duplex_Master
PJ11.Signal=SPI5_MISO
PK0.GPIO_Label=LED_DRV_SPI_SCK
PK0.GPIO_Speed=GPIO_SPEED_FREQ_MEDIUM
PK0.Mode=Full_Duplex_Master
PK0.Signal=SPI5_SCK
PK1.GPIO_Label=LED_DRV_SPI_NSSA
PK1.GPIO_Speed=GPIO_SPEED_FREQ_MEDIUM
PK1.PinState=GPIO_PIN_SET
PK1.Signal=GPIO_Output
ProjectManager.HeapSize=0x2000
ProjectManager.StackSize=0x2000
ProjectManager.TargetToolchain=CMake
QUADSPI.ClockPrescaler=3
QUADSPI.FifoThreshold=4
QUADSPI.FlashSize=22
QUADSPI.SampleShifting=QSPI_SAMPLE_SHIFTING_HALFCYCLE
RCC.ADCFreq_Value=80000000
RCC.APB1Freq_Value=120000000
RCC.APB2Freq_Value=120000000
RCC.APB3Freq_Value=120000000
RCC.APB4Freq_Value=120000000
RCC.CKPERSourceSelection=RCC_CLKPSOURCE_HSE
RCC.CortexFreq_Value=480000000
RCC.D1PPRE=RCC_APB3_DIV2
RCC.D2PPRE1=RCC_APB1_DIV2
RCC.D2PPRE2=RCC_APB2_DIV2
RCC.D3PPRE=RCC_APB4_DIV2
RCC.DIVM1=5
RCC.DIVM2=5
RCC.DIVM3=5
RCC.DIVN1=192
RCC.DIVN2=80
RCC.DIVN3=192
RCC.DIVP2=5
RCC.DIVQ1=12
RCC.DIVQ3=20
RCC.DIVR2=1
RCC.DIVR3=10
RCC.HCLKFreq_Value=240000000
RCC.HPRE=RCC_HCLK_DIV2
RCC.PLL1_VCO_SEL-AdvancedSettings=RCC_PLL1VCOMEDIUM
RCC.PLL2FRACN=0
RCC.PLL2_VCI_Range-AdvancedSettings=RCC_PLL2VCIRANGE_1
RCC.PLL3_VCO_SEL-AdvancedSettings=RCC_PLL3VCOMEDIUM
RCC.PLLFRACN=0
RCC.PLLSourceVirtual=RCC_PLLSOURCE_HSE
RCC.SYSCLKFreq_VALUE=480000000
RCC.SYSCLKSource=RCC_SYSCLKSOURCE_PLLCLK
RCC.SupplySource=PWR_LDO_SUPPLY
RCC.USBCLockSelection=RCC_USBCLKSOURCE_HSI48
RCC.USBFreq_Value=48000000
SH.ADCx_INP5.0=ADC1_INP5,IN5-Single-Ended
SH.ADCx_INP9.0=ADC1_INP9,IN9-Single-Ended
SPI2.BaudRatePrescaler=SPI_BAUDRATEPRESCALER_16
SPI2.CalculateBaudRate=5.0 MBits/s
SPI2.DataSize=SPI_DATASIZE_8BIT
SPI2.Direction=SPI_DIRECTION_2LINES
SPI2.MasterKeepIOState=SPI_MASTER_KEEP_IO_STATE_ENABLE
SPI2.Mode=SPI_MODE_MASTER
SPI2.NSSPMode=SPI_NSS_PULSE_DISABLE
SPI2.VirtualType=VM_MASTER
SPI5.BaudRatePrescaler=SPI_BAUDRATEPRESCALER_16
SPI5.CalculateBaudRate=7.5 MBits/s
SPI5.DataSize=SPI_DATASIZE_8BIT
SPI5.Direction=SPI_DIRECTION_2LINES
SPI5.MasterKeepIOState=SPI_MASTER_KEEP_IO_STATE_DISABLE
SPI5.MasterSSIdleness=SPI_MASTER_SS_IDLENESS_01CYCLE
SPI5.Mode=SPI_MODE_MASTER
SPI5.NSSPMode=SPI_NSS_PULSE_DISABLE
SPI5.VirtualType=VM_MASTER
TIM2.AutoReloadPreload=TIM_AUTORELOAD_PRELOAD_ENABLE
TIM2.Period=100-1
TIM2.Prescaler=240-1
TIM2.TIM_MasterOutputTrigger=TIM_TRGO_UPDATE
UART7.BaudRate=921600
UART7.FIFOMode=FIFOMODE_ENABLE
UART7.RXFIFOThreshold=RXFIFO_THRESHOLD_1QUARTERFULL
UART7.TXFIFOThreshold=TXFIFO_THRESHOLD_1QUARTERFULL
UART8.BaudRate=921600
UART8.FIFOMode=FIFOMODE_ENABLE
UART8.OverrunDisableParam=UART_ADVFEATURE_OVERRUN_ENABLE
UART8.RXFIFOThreshold=RXFIFO_THRESHOLD_1QUARTERFULL
UART8.TXFIFOThreshold=TXFIFO_THRESHOLD_1QUARTERFULL
USART2.BaudRate=921600
USART2.FIFOMode=FIFOMODE_ENABLE
USART2.RXFIFOThreshold=RXFIFO_THRESHOLD_1QUARTERFULL
USART2.TXFIFOThreshold=TXFIFO_THRESHOLD_1QUARTERFULL
USART2.VirtualMode-Asynchronous=VM_ASYNC
USB_OTG_FS.VirtualMode=Dual_Role_Device_FS
VP_CRC_VS_CRC.Mode=CRC_Activate
VP_FATFS_VS_Generic.Mode=User_defined
VP_FREERTOS_VS_CMSIS_V2.Mode=CMSIS_V2
VP_LWIP_VS_Enabled.Mode=Enabled
VP_MEMORYMAP_VS_MEMORYMAP.Mode=CurAppReg
VP_SYS_VS_tim1.Mode=TIM1
VP_TIM2_VS_ClockSourceINT.Mode=Internal
VP_TIM7_VS_ClockSourceINT.Mode=Enable_Timer
VP_USB_OTG_FS1_USB_OTG_FS_DRD.Mode=activate_FS
board=custom

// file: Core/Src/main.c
/* USER CODE BEGIN Header */
/**
  ******************************************************************************
  * @file           : main.c
  * @brief          : Main program body
  ******************************************************************************
  * @attention
  *
  * Copyright (c) 2025 STMicroelectronics.
  * All rights reserved.
  *
  * This software is licensed under terms that can be found in the LICENSE file
  * in the root directory of this software component.
  * If no LICENSE file comes with this software, it is provided AS-IS.
  *
  ******************************************************************************
  */
/* USER CODE END Header */
#include "main.h"
#include "FreeRTOS.h"
#include "cmsis_os2.h"
#include "fatfs.h"
#include "lwip.h"

/* USER CODE BEGIN Includes */
#include "eth_udp_socket.h"
#include "agr_dop_udp.h"
#include "am_drv.h"
#include "agr_boot_core.h"
#include "ioif_agrb_dwt.h"
#include "hardfault_dump.h"   /* Step B 재설계 #1: `.noinit` 덤프 부팅 복원 */
/* USER CODE END Includes */

typedef StaticTask_t osStaticThreadDef_t;

ADC_HandleTypeDef hadc1;
ADC_HandleTypeDef hadc2;
DMA_HandleTypeDef hdma_adc1;
DMA_HandleTypeDef hdma_adc2;

CRC_HandleTypeDef hcrc;

FDCAN_HandleTypeDef hfdcan1;
FDCAN_HandleTypeDef hfdcan2;

I2C_HandleTypeDef hi2c1;

QSPI_HandleTypeDef hqspi;
MDMA_HandleTypeDef hmdma_quadspi_fifo_th;

SPI_HandleTypeDef hspi2;
SPI_HandleTypeDef hspi5;
DMA_HandleTypeDef hdma_spi2_tx;
DMA_HandleTypeDef hdma_spi2_rx;
DMA_HandleTypeDef hdma_spi5_tx;
DMA_HandleTypeDef hdma_spi5_rx;

TIM_HandleTypeDef htim2;
TIM_HandleTypeDef htim7;

UART_HandleTypeDef huart7;
UART_HandleTypeDef huart8;
UART_HandleTypeDef huart2;
DMA_HandleTypeDef hdma_uart7_rx;
DMA_HandleTypeDef hdma_uart7_tx;
DMA_HandleTypeDef hdma_uart8_rx;
DMA_HandleTypeDef hdma_uart8_tx;
DMA_HandleTypeDef hdma_usart2_rx;
DMA_HandleTypeDef hdma_usart2_tx;

PCD_HandleTypeDef hpcd_USB_OTG_FS;
HCD_HandleTypeDef hhcd_USB_OTG_FS;

/* Definitions for DefaultTask */
osThreadId_t DefaultTaskHandle;
uint32_t DefaultTaskBuffer[ 2048 ];
osStaticThreadDef_t DefaultTaskControlBlock;
const osThreadAttr_t DefaultTask_attributes = {
  .name = "DefaultTask",
  .cb_mem = &DefaultTaskControlBlock,
  .cb_size = sizeof(DefaultTaskControlBlock),
  .stack_mem = &DefaultTaskBuffer[0],
  .stack_size = sizeof(DefaultTaskBuffer),
  .priority = (osPriority_t) osPriorityLow,
};
/* Definitions for UserTask */
osThreadId_t UserTaskHandle;
const osThreadAttr_t UserTask_attributes = {
  .name = "UserTask",
  .stack_size = 8192 * 4,
  .priority = (osPriority_t) osPriorityRealtime6,
};
/* Definitions for StartupTask */
osThreadId_t StartupTaskHandle;
const osThreadAttr_t StartupTask_attributes = {
  .name = "StartupTask",
  .stack_size = 512 * 4,
  .priority = (osPriority_t) osPriorityRealtime7,
};

void SystemClock_Config(void);
void PeriphCommonClock_Config(void);
static void MPU_Config(void);
static void MX_GPIO_Init(void);
static void MX_DMA_Init(void);
static void MX_MDMA_Init(void);
static void MX_I2C1_Init(void);
static void MX_UART8_Init(void);
static void MX_FDCAN1_Init(void);
static void MX_ADC1_Init(void);
static void MX_ADC2_Init(void);
static void MX_FDCAN2_Init(void);
static void MX_TIM2_Init(void);
static void MX_QUADSPI_Init(void);
static void MX_USB_OTG_FS_PCD_Init(void);
static void MX_SPI2_Init(void);
static void MX_SPI5_Init(void);
static void MX_UART7_Init(void);
static void MX_USART2_UART_Init(void);
static void MX_CRC_Init(void);
static void MX_TIM7_Init(void);
void StartDefaultTask(void *argument);
void StartUserTask(void *argument);
void StartStartupTask(void *argument);

/* USER CODE BEGIN 0 */

/**
 * @brief Safe __io_putchar stub (prevents HardFault from printf/LWIP_ASSERT)
 * @details syscalls.c의 _write()가 __io_putchar(weak)를 호출하는데,
 *          strong 정의가 없으면 주소 0으로 점프 → UsageFault → HardFault.
 *          향후 SWO/UART retarget 구현 시 이 함수를 교체하면 됨.
 */
int __io_putchar(int ch)
{
    (void)ch;
    return ch;
}

/* USER CODE END 0 */

int main(void)
{

  /* USER CODE BEGIN 1 */

  /* Why: App runs at 0x08040400 when booted via AGR_BOOT V2 bootloader.
   *      VTOR must be set before HAL_Init() because SysTick ISR uses vector table.
   * What: [AS-IS] VTOR = 0x08000000 (default, standalone)
   *       [TO-BE] VTOR = 0x08040400 (AGR_BOOT Active Slot + 1KB header)
   * Impact: All interrupt vectors correctly point to App handlers.
   */
  SCB->VTOR = 0x08040400U;

  /* RCC->RSR snapshot + RMVF clear — 직전 boot 의 reset 원인을 정확히 분리.
   * STM32H7 RSR 은 software clear 안 하면 모든 boot 의 flag 누적. CubeProgrammer
   * 로 g_last_rcc_rsr (.noinit) read 시 직전 reset 만 set 된 깨끗한 값 확인. */
  {
      extern volatile uint32_t g_last_rcc_rsr;
      g_last_rcc_rsr = RCC->RSR;
      __HAL_RCC_CLEAR_RESET_FLAGS();
  }

  /* USER CODE END 1 */

  /* MPU Configuration--------------------------------------------------------*/
  MPU_Config();

  /* Enable the CPU Cache */

  /* Enable I-Cache---------------------------------------------------------*/
  SCB_EnableICache();

  /* Enable D-Cache---------------------------------------------------------*/
  SCB_EnableDCache();

  /* MCU Configuration--------------------------------------------------------*/

  /* Reset of all peripherals, Initializes the Flash interface and the Systick. */
  HAL_Init();

  /* Configure the system clock */
  SystemClock_Config();

  /* Configure the peripherals common clocks */
  PeriphCommonClock_Config();

  /* USER CODE BEGIN SysInit */

  /* Step B 재설계 #1: `.noinit` HardFault 덤프가 있으면 내부 버퍼로 이관.
   * `.noinit` magic 은 여기서 clear → reset loop 시 false positive 방지.
   * 실제 파일 기록은 USB mount 완료 후 DataLogger 초기화 경로에서 처리. */
  (void)HardFault_LoadBootDump();

  /* USER CODE END SysInit */

  /* Initialize all configured peripherals */
  MX_GPIO_Init();
  MX_DMA_Init();
  MX_MDMA_Init();
  MX_I2C1_Init();
  MX_UART8_Init();
  MX_FATFS_Init();
  MX_FDCAN1_Init();
  MX_ADC1_Init();
  MX_ADC2_Init();
  MX_FDCAN2_Init();
  MX_TIM2_Init();
  MX_QUADSPI_Init();
  MX_USB_OTG_FS_PCD_Init();
  MX_SPI2_Init();
  MX_SPI5_Init();
  MX_UART7_Init();
  MX_USART2_UART_Init();
  MX_CRC_Init();
  MX_TIM7_Init();
  /* USER CODE BEGIN 2 */

  /* DWT Cycle Counter 활성화 — PDO 수신 간격 측정용 (cm_drv.c s_dbg_pdo_*) */
  IOIF_DWT_Init();

  /* Why: Notify bootloader that App started successfully.
   * What: Resets boot_count to 0 if update_state == PENDING_CONFIRM.
   * Impact: Prevents BL rollback after max_boot_attempts (default 3).
   *         Safe no-op if Boot Config is absent or not in PENDING state.
   */
  AGR_Boot_ConfirmBoot();

  /* USER CODE END 2 */

  /* Init scheduler */
  osKernelInitialize();

  /* Create the thread(s) */
  /* creation of DefaultTask */
  DefaultTaskHandle = osThreadNew(StartDefaultTask, NULL, &DefaultTask_attributes);

  /* creation of UserTask */
  UserTaskHandle = osThreadNew(StartUserTask, NULL, &UserTask_attributes);

  /* creation of StartupTask */
  StartupTaskHandle = osThreadNew(StartStartupTask, NULL, &StartupTask_attributes);

  /* USER CODE BEGIN RTOS_THREADS */
  /* add threads, ... */

  /* [CRITICAL] UserTask Priority Override
   * - IOC 설정값(Realtime4)을 Realtime6으로 상향
   * - FDCAN RxTask(Realtime7)보다 낮음: PDO 도착 즉시 선점 처리 → stale data 방지
   * - RxTask 선점 ~10-50µs/회 → UserTask 지터 무시 가능
   */
  osThreadSetPriority(UserTaskHandle, osPriorityRealtime6);

  osThreadSuspend(DefaultTaskHandle);
  osThreadSuspend(UserTaskHandle);
  /* USER CODE END RTOS_THREADS */

  /* Start scheduler */
  osKernelStart();

  /* We should never get here as control is now taken by the scheduler */

  /* Infinite loop */
  while (1)
  {

  }
}

void SystemClock_Config(void)
{
  RCC_OscInitTypeDef RCC_OscInitStruct = {0};
  RCC_ClkInitTypeDef RCC_ClkInitStruct = {0};

  /** Supply configuration update enable
  */
  HAL_PWREx_ConfigSupply(PWR_LDO_SUPPLY);

  /** Configure the main internal regulator output voltage
  */
  __HAL_PWR_VOLTAGESCALING_CONFIG(PWR_REGULATOR_VOLTAGE_SCALE0);

  while(!__HAL_PWR_GET_FLAG(PWR_FLAG_VOSRDY)) {}

  /** Initializes the RCC Oscillators according to the specified parameters
  * in the RCC_OscInitTypeDef structure.
  */
  RCC_OscInitStruct.OscillatorType = RCC_OSCILLATORTYPE_HSI48|RCC_OSCILLATORTYPE_HSE;
  RCC_OscInitStruct.HSEState = RCC_HSE_ON;
  RCC_OscInitStruct.HSI48State = RCC_HSI48_ON;
  RCC_OscInitStruct.PLL.PLLState = RCC_PLL_ON;
  RCC_OscInitStruct.PLL.PLLSource = RCC_PLLSOURCE_HSE;
  RCC_OscInitStruct.PLL.PLLM = 5;
  RCC_OscInitStruct.PLL.PLLN = 192;
  RCC_OscInitStruct.PLL.PLLP = 2;
  RCC_OscInitStruct.PLL.PLLQ = 12;
  RCC_OscInitStruct.PLL.PLLR = 2;
  RCC_OscInitStruct.PLL.PLLRGE = RCC_PLL1VCIRANGE_2;
  RCC_OscInitStruct.PLL.PLLVCOSEL = RCC_PLL1VCOWIDE;
  RCC_OscInitStruct.PLL.PLLFRACN = 0;
  if (HAL_RCC_OscConfig(&RCC_OscInitStruct) != HAL_OK)
  {
    Error_Handler();
  }

  /** Initializes the CPU, AHB and APB buses clocks
  */
  RCC_ClkInitStruct.ClockType = RCC_CLOCKTYPE_HCLK|RCC_CLOCKTYPE_SYSCLK
                              |RCC_CLOCKTYPE_PCLK1|RCC_CLOCKTYPE_PCLK2
                              |RCC_CLOCKTYPE_D3PCLK1|RCC_CLOCKTYPE_D1PCLK1;
  RCC_ClkInitStruct.SYSCLKSource = RCC_SYSCLKSOURCE_PLLCLK;
  RCC_ClkInitStruct.SYSCLKDivider = RCC_SYSCLK_DIV1;
  RCC_ClkInitStruct.AHBCLKDivider = RCC_HCLK_DIV2;
  RCC_ClkInitStruct.APB3CLKDivider = RCC_APB3_DIV2;
  RCC_ClkInitStruct.APB1CLKDivider = RCC_APB1_DIV2;
  RCC_ClkInitStruct.APB2CLKDivider = RCC_APB2_DIV2;
  RCC_ClkInitStruct.APB4CLKDivider = RCC_APB4_DIV2;

  if (HAL_RCC_ClockConfig(&RCC_ClkInitStruct, FLASH_LATENCY_4) != HAL_OK)
  {
    Error_Handler();
  }
}

void PeriphCommonClock_Config(void)
{
  RCC_PeriphCLKInitTypeDef PeriphClkInitStruct = {0};

  /** Initializes the peripherals clock
  */
  PeriphClkInitStruct.PeriphClockSelection = RCC_PERIPHCLK_ADC;
  PeriphClkInitStruct.PLL2.PLL2M = 5;
  PeriphClkInitStruct.PLL2.PLL2N = 80;
  PeriphClkInitStruct.PLL2.PLL2P = 5;
  PeriphClkInitStruct.PLL2.PLL2Q = 2;
  PeriphClkInitStruct.PLL2.PLL2R = 1;
  PeriphClkInitStruct.PLL2.PLL2RGE = RCC_PLL2VCIRANGE_2;
  PeriphClkInitStruct.PLL2.PLL2VCOSEL = RCC_PLL2VCOWIDE;
  PeriphClkInitStruct.PLL2.PLL2FRACN = 0;
  PeriphClkInitStruct.AdcClockSelection = RCC_ADCCLKSOURCE_PLL2;
  if (HAL_RCCEx_PeriphCLKConfig(&PeriphClkInitStruct) != HAL_OK)
  {
    Error_Handler();
  }
}

static void MX_ADC1_Init(void)
{

  ADC_MultiModeTypeDef multimode = {0};
  ADC_ChannelConfTypeDef sConfig = {0};

  /** Common config
  */
  hadc1.Instance = ADC1;
  hadc1.Init.ClockPrescaler = ADC_CLOCK_ASYNC_DIV4;
  hadc1.Init.Resolution = ADC_RESOLUTION_16B;
  hadc1.Init.ScanConvMode = ADC_SCAN_ENABLE;
  hadc1.Init.EOCSelection = ADC_EOC_SEQ_CONV;
  hadc1.Init.LowPowerAutoWait = DISABLE;
  hadc1.Init.ContinuousConvMode = DISABLE;
  hadc1.Init.NbrOfConversion = 4;
  hadc1.Init.DiscontinuousConvMode = DISABLE;
  hadc1.Init.ExternalTrigConv = ADC_EXTERNALTRIG_T2_TRGO;
  hadc1.Init.ExternalTrigConvEdge = ADC_EXTERNALTRIGCONVEDGE_RISING;
  hadc1.Init.ConversionDataManagement = ADC_CONVERSIONDATA_DMA_CIRCULAR;
  hadc1.Init.Overrun = ADC_OVR_DATA_OVERWRITTEN;
  hadc1.Init.LeftBitShift = ADC_LEFTBITSHIFT_NONE;
  hadc1.Init.OversamplingMode = DISABLE;
  hadc1.Init.Oversampling.Ratio = 1;
  if (HAL_ADC_Init(&hadc1) != HAL_OK)
  {
    Error_Handler();
  }

  /** Configure the ADC multi-mode
  */
  multimode.Mode = ADC_MODE_INDEPENDENT;
  if (HAL_ADCEx_MultiModeConfigChannel(&hadc1, &multimode) != HAL_OK)
  {
    Error_Handler();
  }

  /** Configure Regular Channel
  */
  sConfig.Channel = ADC_CHANNEL_2;
  sConfig.Rank = ADC_REGULAR_RANK_1;
  sConfig.SamplingTime = ADC_SAMPLETIME_387CYCLES_5;
  sConfig.SingleDiff = ADC_SINGLE_ENDED;
  sConfig.OffsetNumber = ADC_OFFSET_NONE;
  sConfig.Offset = 0;
  sConfig.OffsetSignedSaturation = DISABLE;
  if (HAL_ADC_ConfigChannel(&hadc1, &sConfig) != HAL_OK)
  {
    Error_Handler();
  }

  /** Configure Regular Channel
  */
  sConfig.Channel = ADC_CHANNEL_5;
  sConfig.Rank = ADC_REGULAR_RANK_2;
  if (HAL_ADC_ConfigChannel(&hadc1, &sConfig) != HAL_OK)
  {
    Error_Handler();
  }

  /** Configure Regular Channel
  */
  sConfig.Channel = ADC_CHANNEL_6;
  sConfig.Rank = ADC_REGULAR_RANK_3;
  if (HAL_ADC_ConfigChannel(&hadc1, &sConfig) != HAL_OK)
  {
    Error_Handler();
  }

  /** Configure Regular Channel
  */
  sConfig.Channel = ADC_CHANNEL_9;
  sConfig.Rank = ADC_REGULAR_RANK_4;
  if (HAL_ADC_ConfigChannel(&hadc1, &sConfig) != HAL_OK)
  {
    Error_Handler();
  }

}

static void MX_ADC2_Init(void)
{

  ADC_ChannelConfTypeDef sConfig = {0};

  /** Common config
  */
  hadc2.Instance = ADC2;
  hadc2.Init.ClockPrescaler = ADC_CLOCK_ASYNC_DIV4;
  hadc2.Init.Resolution = ADC_RESOLUTION_12B;
  hadc2.Init.ScanConvMode = ADC_SCAN_ENABLE;
  hadc2.Init.EOCSelection = ADC_EOC_SEQ_CONV;
  hadc2.Init.LowPowerAutoWait = DISABLE;
  hadc2.Init.ContinuousConvMode = DISABLE;
  hadc2.Init.NbrOfConversion = 2;
  hadc2.Init.DiscontinuousConvMode = DISABLE;
  hadc2.Init.ExternalTrigConv = ADC_EXTERNALTRIG_T2_TRGO;
  hadc2.Init.ExternalTrigConvEdge = ADC_EXTERNALTRIGCONVEDGE_RISING;
  hadc2.Init.ConversionDataManagement = ADC_CONVERSIONDATA_DMA_CIRCULAR;
  hadc2.Init.Overrun = ADC_OVR_DATA_OVERWRITTEN;
  hadc2.Init.LeftBitShift = ADC_LEFTBITSHIFT_NONE;
  hadc2.Init.OversamplingMode = DISABLE;
  hadc2.Init.Oversampling.Ratio = 1;
  if (HAL_ADC_Init(&hadc2) != HAL_OK)
  {
    Error_Handler();
  }

  /** Configure Regular Channel
  */
  sConfig.Channel = ADC_CHANNEL_2;
  sConfig.Rank = ADC_REGULAR_RANK_1;
  sConfig.SamplingTime = ADC_SAMPLETIME_810CYCLES_5;
  sConfig.SingleDiff = ADC_SINGLE_ENDED;
  sConfig.OffsetNumber = ADC_OFFSET_NONE;
  sConfig.Offset = 0;
  sConfig.OffsetSignedSaturation = DISABLE;
  if (HAL_ADC_ConfigChannel(&hadc2, &sConfig) != HAL_OK)
  {
    Error_Handler();
  }

  /** Configure Regular Channel
  */
  sConfig.Channel = ADC_CHANNEL_6;
  sConfig.Rank = ADC_REGULAR_RANK_2;
  if (HAL_ADC_ConfigChannel(&hadc2, &sConfig) != HAL_OK)
  {
    Error_Handler();
  }

}

static void MX_CRC_Init(void)
{

  hcrc.Instance = CRC;
  hcrc.Init.DefaultPolynomialUse = DEFAULT_POLYNOMIAL_ENABLE;
  hcrc.Init.DefaultInitValueUse = DEFAULT_INIT_VALUE_ENABLE;
  hcrc.Init.InputDataInversionMode = CRC_INPUTDATA_INVERSION_NONE;
  hcrc.Init.OutputDataInversionMode = CRC_OUTPUTDATA_INVERSION_DISABLE;
  hcrc.InputDataFormat = CRC_INPUTDATA_FORMAT_BYTES;
  if (HAL_CRC_Init(&hcrc) != HAL_OK)
  {
    Error_Handler();
  }

}

static void MX_FDCAN1_Init(void)
{

  hfdcan1.Instance = FDCAN1;
  hfdcan1.Init.FrameFormat = FDCAN_FRAME_FD_BRS;
  hfdcan1.Init.Mode = FDCAN_MODE_NORMAL;
  hfdcan1.Init.AutoRetransmission = ENABLE;
  hfdcan1.Init.TransmitPause = ENABLE;
  hfdcan1.Init.ProtocolException = DISABLE;
  hfdcan1.Init.NominalPrescaler = 10;
  hfdcan1.Init.NominalSyncJumpWidth = 2;
  hfdcan1.Init.NominalTimeSeg1 = 5;
  hfdcan1.Init.NominalTimeSeg2 = 2;
  hfdcan1.Init.DataPrescaler = 1;
  hfdcan1.Init.DataSyncJumpWidth = 4;
  hfdcan1.Init.DataTimeSeg1 = 11;
  hfdcan1.Init.DataTimeSeg2 = 4;
  hfdcan1.Init.MessageRAMOffset = 0;
  hfdcan1.Init.StdFiltersNbr = 28;
  hfdcan1.Init.ExtFiltersNbr = 0;
  hfdcan1.Init.RxFifo0ElmtsNbr = 37;
  hfdcan1.Init.RxFifo0ElmtSize = FDCAN_DATA_BYTES_64;
  hfdcan1.Init.RxFifo1ElmtsNbr = 0;
  hfdcan1.Init.RxFifo1ElmtSize = FDCAN_DATA_BYTES_64;
  hfdcan1.Init.RxBuffersNbr = 0;
  hfdcan1.Init.RxBufferSize = FDCAN_DATA_BYTES_64;
  hfdcan1.Init.TxEventsNbr = 0;
  hfdcan1.Init.TxBuffersNbr = 0;
  hfdcan1.Init.TxFifoQueueElmtsNbr = 32;
  hfdcan1.Init.TxFifoQueueMode = FDCAN_TX_QUEUE_OPERATION;
  hfdcan1.Init.TxElmtSize = FDCAN_DATA_BYTES_64;
  if (HAL_FDCAN_Init(&hfdcan1) != HAL_OK)
  {
    Error_Handler();
  }

}

static void MX_FDCAN2_Init(void)
{

  hfdcan2.Instance = FDCAN2;
  hfdcan2.Init.FrameFormat = FDCAN_FRAME_FD_BRS;
  hfdcan2.Init.Mode = FDCAN_MODE_NORMAL;
  hfdcan2.Init.AutoRetransmission = ENABLE;
  hfdcan2.Init.TransmitPause = ENABLE;
  hfdcan2.Init.ProtocolException = DISABLE;
  hfdcan2.Init.NominalPrescaler = 10;
  hfdcan2.Init.NominalSyncJumpWidth = 2;
  hfdcan2.Init.NominalTimeSeg1 = 5;
  hfdcan2.Init.NominalTimeSeg2 = 2;
  hfdcan2.Init.DataPrescaler = 1;
  hfdcan2.Init.DataSyncJumpWidth = 4;
  hfdcan2.Init.DataTimeSeg1 = 11;
  hfdcan2.Init.DataTimeSeg2 = 4;
  hfdcan2.Init.MessageRAMOffset = 1280;
  hfdcan2.Init.StdFiltersNbr = 28;
  hfdcan2.Init.ExtFiltersNbr = 0;
  hfdcan2.Init.RxFifo0ElmtsNbr = 37;
  hfdcan2.Init.RxFifo0ElmtSize = FDCAN_DATA_BYTES_64;
  hfdcan2.Init.RxFifo1ElmtsNbr = 0;
  hfdcan2.Init.RxFifo1ElmtSize = FDCAN_DATA_BYTES_64;
  hfdcan2.Init.RxBuffersNbr = 0;
  hfdcan2.Init.RxBufferSize = FDCAN_DATA_BYTES_64;
  hfdcan2.Init.TxEventsNbr = 0;
  hfdcan2.Init.TxBuffersNbr = 0;
  hfdcan2.Init.TxFifoQueueElmtsNbr = 32;
  hfdcan2.Init.TxFifoQueueMode = FDCAN_TX_QUEUE_OPERATION;
  hfdcan2.Init.TxElmtSize = FDCAN_DATA_BYTES_64;
  if (HAL_FDCAN_Init(&hfdcan2) != HAL_OK)
  {
    Error_Handler();
  }

}

static void MX_I2C1_Init(void)
{

  hi2c1.Instance = I2C1;
  hi2c1.Init.Timing = 0x307075B1;
  hi2c1.Init.OwnAddress1 = 0;
  hi2c1.Init.AddressingMode = I2C_ADDRESSINGMODE_7BIT;
  hi2c1.Init.DualAddressMode = I2C_DUALADDRESS_DISABLE;
  hi2c1.Init.OwnAddress2 = 0;
  hi2c1.Init.OwnAddress2Masks = I2C_OA2_NOMASK;
  hi2c1.Init.GeneralCallMode = I2C_GENERALCALL_DISABLE;
  hi2c1.Init.NoStretchMode = I2C_NOSTRETCH_DISABLE;
  if (HAL_I2C_Init(&hi2c1) != HAL_OK)
  {
    Error_Handler();
  }

  /** Configure Analogue filter
  */
  if (HAL_I2CEx_ConfigAnalogFilter(&hi2c1, I2C_ANALOGFILTER_ENABLE) != HAL_OK)
  {
    Error_Handler();
  }

  /** Configure Digital filter
  */
  if (HAL_I2CEx_ConfigDigitalFilter(&hi2c1, 0) != HAL_OK)
  {
    Error_Handler();
  }

}

static void MX_QUADSPI_Init(void)
{

  /* QUADSPI parameter configuration*/
  hqspi.Instance = QUADSPI;
  hqspi.Init.ClockPrescaler = 3;
  hqspi.Init.FifoThreshold = 4;
  hqspi.Init.SampleShifting = QSPI_SAMPLE_SHIFTING_HALFCYCLE;
  hqspi.Init.FlashSize = 22;
  hqspi.Init.ChipSelectHighTime = QSPI_CS_HIGH_TIME_1_CYCLE;
  hqspi.Init.ClockMode = QSPI_CLOCK_MODE_0;
  hqspi.Init.FlashID = QSPI_FLASH_ID_1;
  hqspi.Init.DualFlash = QSPI_DUALFLASH_DISABLE;
  if (HAL_QSPI_Init(&hqspi) != HAL_OK)
  {
    Error_Handler();
  }

}

static void MX_SPI2_Init(void)
{

  /* SPI2 parameter configuration*/
  hspi2.Instance = SPI2;
  hspi2.Init.Mode = SPI_MODE_MASTER;
  hspi2.Init.Direction = SPI_DIRECTION_2LINES;
  hspi2.Init.DataSize = SPI_DATASIZE_8BIT;
  hspi2.Init.CLKPolarity = SPI_POLARITY_LOW;
  hspi2.Init.CLKPhase = SPI_PHASE_1EDGE;
  hspi2.Init.NSS = SPI_NSS_SOFT;
  hspi2.Init.BaudRatePrescaler = SPI_BAUDRATEPRESCALER_16;
  hspi2.Init.FirstBit = SPI_FIRSTBIT_MSB;
  hspi2.Init.TIMode = SPI_TIMODE_DISABLE;
  hspi2.Init.CRCCalculation = SPI_CRCCALCULATION_DISABLE;
  hspi2.Init.CRCPolynomial = 0x0;
  hspi2.Init.NSSPMode = SPI_NSS_PULSE_DISABLE;
  hspi2.Init.NSSPolarity = SPI_NSS_POLARITY_LOW;
  hspi2.Init.FifoThreshold = SPI_FIFO_THRESHOLD_01DATA;
  hspi2.Init.TxCRCInitializationPattern = SPI_CRC_INITIALIZATION_ALL_ZERO_PATTERN;
  hspi2.Init.RxCRCInitializationPattern = SPI_CRC_INITIALIZATION_ALL_ZERO_PATTERN;
  hspi2.Init.MasterSSIdleness = SPI_MASTER_SS_IDLENESS_00CYCLE;
  hspi2.Init.MasterInterDataIdleness = SPI_MASTER_INTERDATA_IDLENESS_00CYCLE;
  hspi2.Init.MasterReceiverAutoSusp = SPI_MASTER_RX_AUTOSUSP_DISABLE;
  hspi2.Init.MasterKeepIOState = SPI_MASTER_KEEP_IO_STATE_ENABLE;
  hspi2.Init.IOSwap = SPI_IO_SWAP_DISABLE;
  if (HAL_SPI_Init(&hspi2) != HAL_OK)
  {
    Error_Handler();
  }

}

static void MX_SPI5_Init(void)
{

  /* SPI5 parameter configuration*/
  hspi5.Instance = SPI5;
  hspi5.Init.Mode = SPI_MODE_MASTER;
  hspi5.Init.Direction = SPI_DIRECTION_2LINES;
  hspi5.Init.DataSize = SPI_DATASIZE_8BIT;
  hspi5.Init.CLKPolarity = SPI_POLARITY_LOW;
  hspi5.Init.CLKPhase = SPI_PHASE_1EDGE;
  hspi5.Init.NSS = SPI_NSS_SOFT;
  hspi5.Init.BaudRatePrescaler = SPI_BAUDRATEPRESCALER_16;
  hspi5.Init.FirstBit = SPI_FIRSTBIT_MSB;
  hspi5.Init.TIMode = SPI_TIMODE_DISABLE;
  hspi5.Init.CRCCalculation = SPI_CRCCALCULATION_DISABLE;
  hspi5.Init.CRCPolynomial = 0x0;
  hspi5.Init.NSSPMode = SPI_NSS_PULSE_DISABLE;
  hspi5.Init.NSSPolarity = SPI_NSS_POLARITY_LOW;
  hspi5.Init.FifoThreshold = SPI_FIFO_THRESHOLD_01DATA;
  hspi5.Init.TxCRCInitializationPattern = SPI_CRC_INITIALIZATION_ALL_ZERO_PATTERN;
  hspi5.Init.RxCRCInitializationPattern = SPI_CRC_INITIALIZATION_ALL_ZERO_PATTERN;
  hspi5.Init.MasterSSIdleness = SPI_MASTER_SS_IDLENESS_01CYCLE;
  hspi5.Init.MasterInterDataIdleness = SPI_MASTER_INTERDATA_IDLENESS_00CYCLE;
  hspi5.Init.MasterReceiverAutoSusp = SPI_MASTER_RX_AUTOSUSP_DISABLE;
  hspi5.Init.MasterKeepIOState = SPI_MASTER_KEEP_IO_STATE_DISABLE;
  hspi5.Init.IOSwap = SPI_IO_SWAP_DISABLE;
  if (HAL_SPI_Init(&hspi5) != HAL_OK)
  {
    Error_Handler();
  }

}

static void MX_TIM2_Init(void)
{

  TIM_ClockConfigTypeDef sClockSourceConfig = {0};
  TIM_MasterConfigTypeDef sMasterConfig = {0};

  htim2.Instance = TIM2;
  htim2.Init.Prescaler = 240-1;
  htim2.Init.CounterMode = TIM_COUNTERMODE_UP;
  htim2.Init.Period = 100-1;
  htim2.Init.ClockDivision = TIM_CLOCKDIVISION_DIV1;
  htim2.Init.AutoReloadPreload = TIM_AUTORELOAD_PRELOAD_ENABLE;
  if (HAL_TIM_Base_Init(&htim2) != HAL_OK)
  {
    Error_Handler();
  }
  sClockSourceConfig.ClockSource = TIM_CLOCKSOURCE_INTERNAL;
  if (HAL_TIM_ConfigClockSource(&htim2, &sClockSourceConfig) != HAL_OK)
  {
    Error_Handler();
  }
  sMasterConfig.MasterOutputTrigger = TIM_TRGO_UPDATE;
  sMasterConfig.MasterSlaveMode = TIM_MASTERSLAVEMODE_DISABLE;
  if (HAL_TIMEx_MasterConfigSynchronization(&htim2, &sMasterConfig) != HAL_OK)
  {
    Error_Handler();
  }

}

static void MX_TIM7_Init(void)
{

  TIM_MasterConfigTypeDef sMasterConfig = {0};

  htim7.Instance = TIM7;
  htim7.Init.Prescaler = 0;
  htim7.Init.CounterMode = TIM_COUNTERMODE_UP;
  htim7.Init.Period = 65535;
  htim7.Init.AutoReloadPreload = TIM_AUTORELOAD_PRELOAD_DISABLE;
  if (HAL_TIM_Base_Init(&htim7) != HAL_OK)
  {
    Error_Handler();
  }
  sMasterConfig.MasterOutputTrigger = TIM_TRGO_RESET;
  sMasterConfig.MasterSlaveMode = TIM_MASTERSLAVEMODE_DISABLE;
  if (HAL_TIMEx_MasterConfigSynchronization(&htim7, &sMasterConfig) != HAL_OK)
  {
    Error_Handler();
  }

}

static void MX_UART7_Init(void)
{

  huart7.Instance = UART7;
  huart7.Init.BaudRate = 921600;
  huart7.Init.WordLength = UART_WORDLENGTH_8B;
  huart7.Init.StopBits = UART_STOPBITS_1;
  huart7.Init.Parity = UART_PARITY_NONE;
  huart7.Init.Mode = UART_MODE_TX_RX;
  huart7.Init.HwFlowCtl = UART_HWCONTROL_NONE;
  huart7.Init.OverSampling = UART_OVERSAMPLING_16;
  huart7.Init.OneBitSampling = UART_ONE_BIT_SAMPLE_DISABLE;
  huart7.Init.ClockPrescaler = UART_PRESCALER_DIV1;
  huart7.AdvancedInit.AdvFeatureInit = UART_ADVFEATURE_NO_INIT;
  if (HAL_UART_Init(&huart7) != HAL_OK)
  {
    Error_Handler();
  }
  if (HAL_UARTEx_SetTxFifoThreshold(&huart7, UART_TXFIFO_THRESHOLD_1_4) != HAL_OK)
  {
    Error_Handler();
  }
  if (HAL_UARTEx_SetRxFifoThreshold(&huart7, UART_RXFIFO_THRESHOLD_1_4) != HAL_OK)
  {
    Error_Handler();
  }
  if (HAL_UARTEx_EnableFifoMode(&huart7) != HAL_OK)
  {
    Error_Handler();
  }

}

static void MX_UART8_Init(void)
{

  huart8.Instance = UART8;
  huart8.Init.BaudRate = 921600;
  huart8.Init.WordLength = UART_WORDLENGTH_8B;
  huart8.Init.StopBits = UART_STOPBITS_1;
  huart8.Init.Parity = UART_PARITY_NONE;
  huart8.Init.Mode = UART_MODE_TX_RX;
  huart8.Init.HwFlowCtl = UART_HWCONTROL_NONE;
  huart8.Init.OverSampling = UART_OVERSAMPLING_16;
  huart8.Init.OneBitSampling = UART_ONE_BIT_SAMPLE_DISABLE;
  huart8.Init.ClockPrescaler = UART_PRESCALER_DIV1;
  huart8.AdvancedInit.AdvFeatureInit = UART_ADVFEATURE_NO_INIT;
  if (HAL_UART_Init(&huart8) != HAL_OK)
  {
    Error_Handler();
  }
  if (HAL_UARTEx_SetTxFifoThreshold(&huart8, UART_TXFIFO_THRESHOLD_1_4) != HAL_OK)
  {
    Error_Handler();
  }
  if (HAL_UARTEx_SetRxFifoThreshold(&huart8, UART_RXFIFO_THRESHOLD_1_4) != HAL_OK)
  {
    Error_Handler();
  }
  if (HAL_UARTEx_EnableFifoMode(&huart8) != HAL_OK)
  {
    Error_Handler();
  }

}

static void MX_USART2_UART_Init(void)
{

  huart2.Instance = USART2;
  huart2.Init.BaudRate = 921600;
  huart2.Init.WordLength = UART_WORDLENGTH_8B;
  huart2.Init.StopBits = UART_STOPBITS_1;
  huart2.Init.Parity = UART_PARITY_NONE;
  huart2.Init.Mode = UART_MODE_TX_RX;
  huart2.Init.HwFlowCtl = UART_HWCONTROL_NONE;
  huart2.Init.OverSampling = UART_OVERSAMPLING_16;
  huart2.Init.OneBitSampling = UART_ONE_BIT_SAMPLE_DISABLE;
  huart2.Init.ClockPrescaler = UART_PRESCALER_DIV1;
  huart2.AdvancedInit.AdvFeatureInit = UART_ADVFEATURE_NO_INIT;
  if (HAL_UART_Init(&huart2) != HAL_OK)
  {
    Error_Handler();
  }
  if (HAL_UARTEx_SetTxFifoThreshold(&huart2, UART_TXFIFO_THRESHOLD_1_4) != HAL_OK)
  {
    Error_Handler();
  }
  if (HAL_UARTEx_SetRxFifoThreshold(&huart2, UART_RXFIFO_THRESHOLD_1_4) != HAL_OK)
  {
    Error_Handler();
  }
  if (HAL_UARTEx_EnableFifoMode(&huart2) != HAL_OK)
  {
    Error_Handler();
  }

}

static void MX_USB_OTG_FS_PCD_Init(void)
{

  hpcd_USB_OTG_FS.Instance = USB_OTG_FS;
  hpcd_USB_OTG_FS.Init.dev_endpoints = 9;
  hpcd_USB_OTG_FS.Init.speed = PCD_SPEED_FULL;
  hpcd_USB_OTG_FS.Init.dma_enable = DISABLE;
  hpcd_USB_OTG_FS.Init.phy_itface = PCD_PHY_EMBEDDED;
  hpcd_USB_OTG_FS.Init.Sof_enable = DISABLE;
  hpcd_USB_OTG_FS.Init.low_power_enable = DISABLE;
  hpcd_USB_OTG_FS.Init.lpm_enable = DISABLE;
  hpcd_USB_OTG_FS.Init.battery_charging_enable = DISABLE;
  hpcd_USB_OTG_FS.Init.vbus_sensing_enable = DISABLE;
  hpcd_USB_OTG_FS.Init.use_dedicated_ep1 = DISABLE;
  if (HAL_PCD_Init(&hpcd_USB_OTG_FS) != HAL_OK)
  {
    Error_Handler();
  }

}

void MX_USB_OTG_FS_HCD_Init(void)
{

  hhcd_USB_OTG_FS.Instance = USB_OTG_FS;
  hhcd_USB_OTG_FS.Init.Host_channels = 16;
  hhcd_USB_OTG_FS.Init.speed = HCD_SPEED_FULL;
  hhcd_USB_OTG_FS.Init.dma_enable = DISABLE;
  hhcd_USB_OTG_FS.Init.phy_itface = HCD_PHY_EMBEDDED;
  hhcd_USB_OTG_FS.Init.Sof_enable = DISABLE;
  if (HAL_HCD_Init(&hhcd_USB_OTG_FS) != HAL_OK)
  {
    Error_Handler();
  }

}

static void MX_DMA_Init(void)
{

  /* DMA controller clock enable */
  __HAL_RCC_DMA1_CLK_ENABLE();
  __HAL_RCC_DMA2_CLK_ENABLE();

  /* DMA interrupt init */
  /* DMA1_Stream0_IRQn interrupt configuration */
  HAL_NVIC_SetPriority(DMA1_Stream0_IRQn, 7, 0);
  HAL_NVIC_EnableIRQ(DMA1_Stream0_IRQn);
  /* DMA1_Stream1_IRQn interrupt configuration */
  HAL_NVIC_SetPriority(DMA1_Stream1_IRQn, 7, 0);
  HAL_NVIC_EnableIRQ(DMA1_Stream1_IRQn);
  /* DMA1_Stream2_IRQn interrupt configuration */
  HAL_NVIC_SetPriority(DMA1_Stream2_IRQn, 6, 0);
  HAL_NVIC_EnableIRQ(DMA1_Stream2_IRQn);
  /* DMA1_Stream3_IRQn interrupt configuration */
  HAL_NVIC_SetPriority(DMA1_Stream3_IRQn, 6, 0);
  HAL_NVIC_EnableIRQ(DMA1_Stream3_IRQn);
  /* DMA1_Stream4_IRQn interrupt configuration */
  HAL_NVIC_SetPriority(DMA1_Stream4_IRQn, 6, 0);
  HAL_NVIC_EnableIRQ(DMA1_Stream4_IRQn);
  /* DMA1_Stream5_IRQn interrupt configuration */
  HAL_NVIC_SetPriority(DMA1_Stream5_IRQn, 6, 0);
  HAL_NVIC_EnableIRQ(DMA1_Stream5_IRQn);
  /* DMA1_Stream6_IRQn interrupt configuration */
  HAL_NVIC_SetPriority(DMA1_Stream6_IRQn, 6, 0);
  HAL_NVIC_EnableIRQ(DMA1_Stream6_IRQn);
  /* DMA1_Stream7_IRQn interrupt configuration */
  HAL_NVIC_SetPriority(DMA1_Stream7_IRQn, 6, 0);
  HAL_NVIC_EnableIRQ(DMA1_Stream7_IRQn);
  /* DMA2_Stream0_IRQn interrupt configuration */
  HAL_NVIC_SetPriority(DMA2_Stream0_IRQn, 6, 0);
  HAL_NVIC_EnableIRQ(DMA2_Stream0_IRQn);
  /* DMA2_Stream1_IRQn interrupt configuration */
  HAL_NVIC_SetPriority(DMA2_Stream1_IRQn, 6, 0);
  HAL_NVIC_EnableIRQ(DMA2_Stream1_IRQn);
  /* DMA2_Stream2_IRQn interrupt configuration */
  HAL_NVIC_SetPriority(DMA2_Stream2_IRQn, 6, 0);
  HAL_NVIC_EnableIRQ(DMA2_Stream2_IRQn);
  /* DMA2_Stream3_IRQn interrupt configuration */
  HAL_NVIC_SetPriority(DMA2_Stream3_IRQn, 6, 0);
  HAL_NVIC_EnableIRQ(DMA2_Stream3_IRQn);

}

/**
  * Enable MDMA controller clock
  */
static void MX_MDMA_Init(void)
{

  /* MDMA controller clock enable */
  __HAL_RCC_MDMA_CLK_ENABLE();
  /* Local variables */

  /* MDMA interrupt initialization */
  /* MDMA_IRQn interrupt configuration */
  HAL_NVIC_SetPriority(MDMA_IRQn, 6, 0);
  HAL_NVIC_EnableIRQ(MDMA_IRQn);

}

static void MX_GPIO_Init(void)
{
  GPIO_InitTypeDef GPIO_InitStruct = {0};

  /* GPIO Ports Clock Enable */
  __HAL_RCC_GPIOG_CLK_ENABLE();
  __HAL_RCC_GPIOD_CLK_ENABLE();
  __HAL_RCC_GPIOC_CLK_ENABLE();
  __HAL_RCC_GPIOA_CLK_ENABLE();
  __HAL_RCC_GPIOI_CLK_ENABLE();
  __HAL_RCC_GPIOE_CLK_ENABLE();
  __HAL_RCC_GPIOB_CLK_ENABLE();
  __HAL_RCC_GPIOH_CLK_ENABLE();
  __HAL_RCC_GPIOF_CLK_ENABLE();
  __HAL_RCC_GPIOK_CLK_ENABLE();
  __HAL_RCC_GPIOJ_CLK_ENABLE();

  /*Configure GPIO pin Output Level */
  HAL_GPIO_WritePin(GPIOG, L_GRF_PWR_EN_Pin|R_GRF_PWR_EN_Pin|HMMG_PWR_EN_Pin|IMU_PWR_EN_Pin
                          |FES_PWR_EN_Pin|EMG_PWR_EN_Pin, GPIO_PIN_RESET);

  /*Configure GPIO pin Output Level */
  HAL_GPIO_WritePin(GPIOA, USB_DFP_UFP_Pin|TP9_Pin|TP8_Pin, GPIO_PIN_RESET);

  /*Configure GPIO pin Output Level */
  HAL_GPIO_WritePin(RTC_SPI_NSSA_GPIO_Port, RTC_SPI_NSSA_Pin, GPIO_PIN_SET);

  /*Configure GPIO pin Output Level */
  HAL_GPIO_WritePin(GPIOH, FUNC_LED_3_Pin|FUNC_LED_2_Pin|FUNC_LED_1_Pin, GPIO_PIN_RESET);

  /*Configure GPIO pin Output Level */
  HAL_GPIO_WritePin(GPIOD, USB_PWR_ON_Pin|TP12_Pin|LED_DRV_nOE_Pin|LED_DRV_nRESET_Pin, GPIO_PIN_RESET);

  /*Configure GPIO pin Output Level */
  HAL_GPIO_WritePin(EXT_PWR_SEL_5V_GPIO_Port, EXT_PWR_SEL_5V_Pin, GPIO_PIN_RESET);

  /*Configure GPIO pin Output Level */
  HAL_GPIO_WritePin(GPIOC, CM_LED_G_Pin|CM_LED_B_Pin|CM_LED_R_Pin|POWER_ON_LED_Pin
                          |MCU_PHY_RST_Pin, GPIO_PIN_RESET);

  /*Configure GPIO pin Output Level */
  HAL_GPIO_WritePin(MCU_RESET_N_GPIO_Port, MCU_RESET_N_Pin, GPIO_PIN_RESET);

  /*Configure GPIO pin Output Level */
  HAL_GPIO_WritePin(LED_DRV_SPI_NSSA_GPIO_Port, LED_DRV_SPI_NSSA_Pin, GPIO_PIN_SET);

  /*Configure GPIO pins : L_GRF_PWR_EN_Pin R_GRF_PWR_EN_Pin HMMG_PWR_EN_Pin IMU_PWR_EN_Pin
                           FES_PWR_EN_Pin EMG_PWR_EN_Pin */
  GPIO_InitStruct.Pin = L_GRF_PWR_EN_Pin|R_GRF_PWR_EN_Pin|HMMG_PWR_EN_Pin|IMU_PWR_EN_Pin
                          |FES_PWR_EN_Pin|EMG_PWR_EN_Pin;
  GPIO_InitStruct.Mode = GPIO_MODE_OUTPUT_PP;
  GPIO_InitStruct.Pull = GPIO_NOPULL;
  GPIO_InitStruct.Speed = GPIO_SPEED_FREQ_LOW;
  HAL_GPIO_Init(GPIOG, &GPIO_InitStruct);

  /*Configure GPIO pins : HMMG__FAULT_Pin L_GRF__FAULT_Pin R_GRF__FAULT_Pin IMU__FAULT_Pin
                           FES__FAULT_Pin EMG__FAULT_Pin HWREV_2_Pin HWREV_1_Pin */
  GPIO_InitStruct.Pin = HMMG__FAULT_Pin|L_GRF__FAULT_Pin|R_GRF__FAULT_Pin|IMU__FAULT_Pin
                          |FES__FAULT_Pin|EMG__FAULT_Pin|HWREV_2_Pin|HWREV_1_Pin;
  GPIO_InitStruct.Mode = GPIO_MODE_INPUT;
  GPIO_InitStruct.Pull = GPIO_NOPULL;
  HAL_GPIO_Init(GPIOG, &GPIO_InitStruct);

  /*Configure GPIO pin : RTC_nINT_Pin */
  GPIO_InitStruct.Pin = RTC_nINT_Pin;
  GPIO_InitStruct.Mode = GPIO_MODE_INPUT;
  GPIO_InitStruct.Pull = GPIO_NOPULL;
  HAL_GPIO_Init(RTC_nINT_GPIO_Port, &GPIO_InitStruct);

  /*Configure GPIO pins : USB_DFP_UFP_Pin TP8_Pin */
  GPIO_InitStruct.Pin = USB_DFP_UFP_Pin|TP8_Pin;
  GPIO_InitStruct.Mode = GPIO_MODE_OUTPUT_PP;
  GPIO_InitStruct.Pull = GPIO_NOPULL;
  GPIO_InitStruct.Speed = GPIO_SPEED_FREQ_LOW;
  HAL_GPIO_Init(GPIOA, &GPIO_InitStruct);

  /*Configure GPIO pin : RTC_SPI_NSSA_Pin */
  GPIO_InitStruct.Pin = RTC_SPI_NSSA_Pin;
  GPIO_InitStruct.Mode = GPIO_MODE_OUTPUT_PP;
  GPIO_InitStruct.Pull = GPIO_NOPULL;
  GPIO_InitStruct.Speed = GPIO_SPEED_FREQ_MEDIUM;
  HAL_GPIO_Init(RTC_SPI_NSSA_GPIO_Port, &GPIO_InitStruct);

  /*Configure GPIO pins : FUNC_BTN_1_Pin FUNC_BTN_2_Pin FUNC_BTN_3_Pin */
  GPIO_InitStruct.Pin = FUNC_BTN_1_Pin|FUNC_BTN_2_Pin|FUNC_BTN_3_Pin;
  GPIO_InitStruct.Mode = GPIO_MODE_INPUT;
  GPIO_InitStruct.Pull = GPIO_NOPULL;
  HAL_GPIO_Init(GPIOC, &GPIO_InitStruct);

  /*Configure GPIO pins : FUNC_LED_3_Pin FUNC_LED_2_Pin FUNC_LED_1_Pin */
  GPIO_InitStruct.Pin = FUNC_LED_3_Pin|FUNC_LED_2_Pin|FUNC_LED_1_Pin;
  GPIO_InitStruct.Mode = GPIO_MODE_OUTPUT_PP;
  GPIO_InitStruct.Pull = GPIO_NOPULL;
  GPIO_InitStruct.Speed = GPIO_SPEED_FREQ_LOW;
  HAL_GPIO_Init(GPIOH, &GPIO_InitStruct);

  /*Configure GPIO pins : USB_PWR_ON_Pin LED_DRV_nOE_Pin LED_DRV_nRESET_Pin */
  GPIO_InitStruct.Pin = USB_PWR_ON_Pin|LED_DRV_nOE_Pin|LED_DRV_nRESET_Pin;
  GPIO_InitStruct.Mode = GPIO_MODE_OUTPUT_PP;
  GPIO_InitStruct.Pull = GPIO_NOPULL;
  GPIO_InitStruct.Speed = GPIO_SPEED_FREQ_LOW;
  HAL_GPIO_Init(GPIOD, &GPIO_InitStruct);

  /*Configure GPIO pin : EXT_PWR_SEL_5V_Pin */
  GPIO_InitStruct.Pin = EXT_PWR_SEL_5V_Pin;
  GPIO_InitStruct.Mode = GPIO_MODE_OUTPUT_PP;
  GPIO_InitStruct.Pull = GPIO_NOPULL;
  GPIO_InitStruct.Speed = GPIO_SPEED_FREQ_LOW;
  HAL_GPIO_Init(EXT_PWR_SEL_5V_GPIO_Port, &GPIO_InitStruct);

  /*Configure GPIO pin : TP12_Pin */
  GPIO_InitStruct.Pin = TP12_Pin;
  GPIO_InitStruct.Mode = GPIO_MODE_OUTPUT_PP;
  GPIO_InitStruct.Pull = GPIO_PULLDOWN;
  GPIO_InitStruct.Speed = GPIO_SPEED_FREQ_LOW;
  HAL_GPIO_Init(TP12_GPIO_Port, &GPIO_InitStruct);

  /*Configure GPIO pins : USB_OTG_FS_VBUS_Pin USB_OC__DET_Pin */
  GPIO_InitStruct.Pin = USB_OTG_FS_VBUS_Pin|USB_OC__DET_Pin;
  GPIO_InitStruct.Mode = GPIO_MODE_INPUT;
  GPIO_InitStruct.Pull = GPIO_NOPULL;
  HAL_GPIO_Init(GPIOA, &GPIO_InitStruct);

  /*Configure GPIO pins : CM_LED_G_Pin CM_LED_B_Pin CM_LED_R_Pin POWER_ON_LED_Pin
                           MCU_PHY_RST_Pin */
  GPIO_InitStruct.Pin = CM_LED_G_Pin|CM_LED_B_Pin|CM_LED_R_Pin|POWER_ON_LED_Pin
                          |MCU_PHY_RST_Pin;
  GPIO_InitStruct.Mode = GPIO_MODE_OUTPUT_PP;
  GPIO_InitStruct.Pull = GPIO_NOPULL;
  GPIO_InitStruct.Speed = GPIO_SPEED_FREQ_LOW;
  HAL_GPIO_Init(GPIOC, &GPIO_InitStruct);

  /*Configure GPIO pin : MCU_RESET_N_Pin */
  GPIO_InitStruct.Pin = MCU_RESET_N_Pin;
  GPIO_InitStruct.Mode = GPIO_MODE_OUTPUT_PP;
  GPIO_InitStruct.Pull = GPIO_NOPULL;
  GPIO_InitStruct.Speed = GPIO_SPEED_FREQ_LOW;
  HAL_GPIO_Init(MCU_RESET_N_GPIO_Port, &GPIO_InitStruct);

  /*Configure GPIO pins : EXT_GPIO_1_Pin EXT_GPIO_3_Pin EXT_GPIO_2_Pin EXT_GPIO_4_Pin
                           EXT_GPIO_5_Pin EXT_GPIO_6_Pin EXT_GPIO_8_Pin EXT_GPIO_7_Pin */
  GPIO_InitStruct.Pin = EXT_GPIO_1_Pin|EXT_GPIO_3_Pin|EXT_GPIO_2_Pin|EXT_GPIO_4_Pin
                          |EXT_GPIO_5_Pin|EXT_GPIO_6_Pin|EXT_GPIO_8_Pin|EXT_GPIO_7_Pin;
  GPIO_InitStruct.Mode = GPIO_MODE_INPUT;
  GPIO_InitStruct.Pull = GPIO_NOPULL;
  HAL_GPIO_Init(GPIOF, &GPIO_InitStruct);

  /*Configure GPIO pin : LED_DRV_SPI_NSSA_Pin */
  GPIO_InitStruct.Pin = LED_DRV_SPI_NSSA_Pin;
  GPIO_InitStruct.Mode = GPIO_MODE_OUTPUT_PP;
  GPIO_InitStruct.Pull = GPIO_NOPULL;
  GPIO_InitStruct.Speed = GPIO_SPEED_FREQ_MEDIUM;
  HAL_GPIO_Init(LED_DRV_SPI_NSSA_GPIO_Port, &GPIO_InitStruct);

  /*Configure GPIO pin : TP9_Pin */
  GPIO_InitStruct.Pin = TP9_Pin;
  GPIO_InitStruct.Mode = GPIO_MODE_OUTPUT_PP;
  GPIO_InitStruct.Pull = GPIO_PULLDOWN;
  GPIO_InitStruct.Speed = GPIO_SPEED_FREQ_LOW;
  HAL_GPIO_Init(TP9_GPIO_Port, &GPIO_InitStruct);

  /*Configure GPIO pin : HWREV_0_Pin */
  GPIO_InitStruct.Pin = HWREV_0_Pin;
  GPIO_InitStruct.Mode = GPIO_MODE_INPUT;
  GPIO_InitStruct.Pull = GPIO_NOPULL;
  HAL_GPIO_Init(HWREV_0_GPIO_Port, &GPIO_InitStruct);

  /*AnalogSwitch Config */
  HAL_SYSCFG_AnalogSwitchConfig(SYSCFG_SWITCH_PC2, SYSCFG_SWITCH_PC2_CLOSE);

}

void StartDefaultTask(void *argument)
{
  /* init code for LWIP */
  MX_LWIP_Init();
  /* USER CODE BEGIN 5 */

  /* --- Rev2.0 AGR_DOP UDP 소켓 초기화 (PDO:5001, SDO:5002, EMCY:5003) ---
   * MX_LWIP_Init() 완료 후 호출. PHY 리셋은 StartupTask(_InitIoInterfaces)에서 완료됨.
   * StartupTask(Realtime7) > DefaultTask(Low) 이므로 PHY 리셋이 반드시 선행됨.
   */
  EthUdpSocket_Init();

  /* --- Rev2.0 AGR_DOP over UDP + AM Device Driver 초기화 ---
   * AM(Jetson) Node ID = 0x01, XM Node ID = 0x02
   * PDO/SDO 수신 → am_drv 콜백 → mutex+snapshot → core_process에서 읽기
   */
  static AGR_DOP_Ctx_t s_udp_dop_ctx;
  AM_Drv_Init(0x01);                             /* AM Node ID = 0x01 (Jetson) */
  AGR_UDP_Init(&s_udp_dop_ctx, NULL, 0x02);      /* XM Node ID = 0x02 */
  AGR_UDP_RegisterPdoCallback(AM_Drv_ProcessPdo); /* PDO → am_drv */
  AGR_UDP_RegisterSdoCallback(AM_Drv_ProcessSdo); /* SDO → am_drv */

  /* Infinite loop */
  for(;;)
  {
    osDelay(1);
  }
  /* USER CODE END 5 */
}

__weak void StartUserTask(void *argument)
{
  for(;;)
  {
    osDelay(1);
  }
}

__weak void StartStartupTask(void *argument)
{
  for(;;)
  {
    osDelay(1);
  }
}

 /* MPU Configuration */

void MPU_Config(void)
{
  MPU_Region_InitTypeDef MPU_InitStruct = {0};

  /* Disables the MPU */
  HAL_MPU_Disable();

  /** Initializes and configures the Region and the memory to be protected
  */
  MPU_InitStruct.Enable = MPU_REGION_ENABLE;
  MPU_InitStruct.Number = MPU_REGION_NUMBER0;
  MPU_InitStruct.BaseAddress = 0x30000000;
  MPU_InitStruct.Size = MPU_REGION_SIZE_256KB;
  MPU_InitStruct.SubRegionDisable = 0x0;
  MPU_InitStruct.TypeExtField = MPU_TEX_LEVEL1;
  MPU_InitStruct.AccessPermission = MPU_REGION_FULL_ACCESS;
  MPU_InitStruct.DisableExec = MPU_INSTRUCTION_ACCESS_DISABLE;
  MPU_InitStruct.IsShareable = MPU_ACCESS_SHAREABLE;
  MPU_InitStruct.IsCacheable = MPU_ACCESS_NOT_CACHEABLE;
  MPU_InitStruct.IsBufferable = MPU_ACCESS_NOT_BUFFERABLE;

  HAL_MPU_ConfigRegion(&MPU_InitStruct);

  /** Initializes and configures the Region and the memory to be protected
  */
  MPU_InitStruct.Number = MPU_REGION_NUMBER1;
  MPU_InitStruct.BaseAddress = 0x30040000;
  MPU_InitStruct.Size = MPU_REGION_SIZE_32KB;

  HAL_MPU_ConfigRegion(&MPU_InitStruct);

  /** Initializes and configures the Region and the memory to be protected
  */
  MPU_InitStruct.Number = MPU_REGION_NUMBER2;
  MPU_InitStruct.BaseAddress = 0x38000000;
  MPU_InitStruct.Size = MPU_REGION_SIZE_64KB;

  HAL_MPU_ConfigRegion(&MPU_InitStruct);

  /** Initializes and configures the Region and the memory to be protected
  */
  MPU_InitStruct.Number = MPU_REGION_NUMBER3;
  MPU_InitStruct.BaseAddress = 0x90000000;
  MPU_InitStruct.Size = MPU_REGION_SIZE_8MB;
  MPU_InitStruct.TypeExtField = MPU_TEX_LEVEL0;
  MPU_InitStruct.DisableExec = MPU_INSTRUCTION_ACCESS_ENABLE;
  MPU_InitStruct.IsShareable = MPU_ACCESS_NOT_SHAREABLE;
  MPU_InitStruct.IsCacheable = MPU_ACCESS_CACHEABLE;

  HAL_MPU_ConfigRegion(&MPU_InitStruct);
  /* Enables the MPU */
  HAL_MPU_Enable(MPU_HFNMI_PRIVDEF);

}

void HAL_TIM_PeriodElapsedCallback(TIM_HandleTypeDef *htim)
{
  if (htim->Instance == TIM1)
  {
    HAL_IncTick();
  }
}

void Error_Handler(void)
{
  /* USER CODE BEGIN Error_Handler_Debug */
  /* [?��?��]
   * ?�� 명령?���??? 추�??���??? 코드�??? ?�� 줄에 ?��?��?��?�� 즉시
   * ?��버거�??? ?��?��?���??? 멈춥?��?��. (Breakpoint?? ?��?��)
   */
  __BKPT(0); // <--- ?�� 줄을 추�??��?��?��.
  /* User can add his own implementation to report the HAL error return state */
  __disable_irq();
  while (1)
  {
  }
  /* USER CODE END Error_Handler_Debug */
}

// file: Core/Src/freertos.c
/* USER CODE BEGIN Header */
/**
  ******************************************************************************
  * File Name          : freertos.c
  * Description        : Code for freertos applications
  ******************************************************************************
  * @attention
  *
  * Copyright (c) 2025 STMicroelectronics.
  * All rights reserved.
  *
  * This software is licensed under terms that can be found in the LICENSE file
  * in the root directory of this software component.
  * If no LICENSE file comes with this software, it is provided AS-IS.
  *
  ******************************************************************************
  */
/* USER CODE END Header */

#include "FreeRTOS.h"
#include "task.h"
#include "main.h"

/* USER CODE BEGIN Variables */
/* Phase 2: FreeRTOS Heap — DTCMRAM (Zero-Wait-State, DMA 접근 불가 → 커널 객체 보호) */
uint8_t ucHeap[configTOTAL_HEAP_SIZE] __attribute__((section(".dtcm_data"), aligned(8)));
/* USER CODE END Variables */

/* Hook prototypes */
void vApplicationStackOverflowHook(xTaskHandle xTask, char *pcTaskName);

/* USER CODE BEGIN 4 */
/* [DIAG 2026-05-12 cross-port from 0428] Stack overflow 검출 진단.
 *  - 이전에는 빈 hook → silent corruption → 이후 freeze/hardfault 의 root cause.
 *  - 활성화 후: stack overflow 발생 즉시 infinite loop 에 진입.
 *    디버거 Suspend 하면 g_overflow_task_name 변수로 어느 task 인지 확인 가능.
 *  - 다음 단계: 식별된 task 의 stack size 를 늘리거나 stack 사용 줄이기. */
/* .noinit 배치 — POR 외 reset (NVIC_SystemReset, lockup auto-reset) 에서 보존.
 * 다음 boot 시 main() 가 g_overflow_detected 검사로 이전 boot 의 stack overflow
 * 흔적 확인 가능. POR 직후엔 random 값일 수 있으므로 detected==1 일 때만 신뢰. */
__attribute__((section(".noinit"), used))
volatile char     g_overflow_task_name[16];
__attribute__((section(".noinit"), used))
volatile uint32_t g_overflow_detected;

/* 직전 boot 시점의 RCC->RSR snapshot — main() 진입 직후 저장 + RMVF clear.
 * STM32H7 RSR 은 software 가 clear 안 하면 모든 boot 의 flag 누적. snapshot
 * + clear 로 정확히 "직전 reset 원인" 만 표시. POR 후엔 random, 이후엔 0xXX
 * 형식의 RSR 값. CubeProgrammer 로 read 가능 (주소 map 에서 확인). */
__attribute__((section(".noinit"), used))
volatile uint32_t g_last_rcc_rsr;

void vApplicationStackOverflowHook(xTaskHandle xTask, char *pcTaskName)
{
    (void)xTask;

    if (pcTaskName != NULL) {
        for (int i = 0; i < 15 && pcTaskName[i] != '\0'; i++) {
            g_overflow_task_name[i] = pcTaskName[i];
        }
        g_overflow_task_name[15] = '\0';
    } else {
        g_overflow_task_name[0] = '?';
        g_overflow_task_name[1] = '\0';
    }
    g_overflow_detected = 1;

    /* Infinite loop — 디버거 Suspend 시 여기서 잡힘. PC + g_overflow_task_name 확인.
     * [Note] 전역 인터럽트는 차단하지 않는다 (hook 정책 + 다른 ISR가 디버거 attach
     *  안정성을 깨뜨릴 만큼 corrupted 영역을 건드릴 가능성 낮음).
     * [Phase 2 RM] LED/CDC 친화 메시지는 XM10 Risk Management 통합 단계에서 도입. */
    for (;;) {
        __NOP();
    }
}

/* USER CODE END 4 */
